[part 14 of 23: package /Cluster]
AUTOSAR XML (schema 4-3-0)
package /Cluster  (continued)
  7 x lin cluster, all with baudrate=19200, protocol-name=LIN, protocol-version=2.0:  (continued)
    Klima_LIN6
      lin physical channel CHNL: comm-connectors=CN_Klima_LIN6
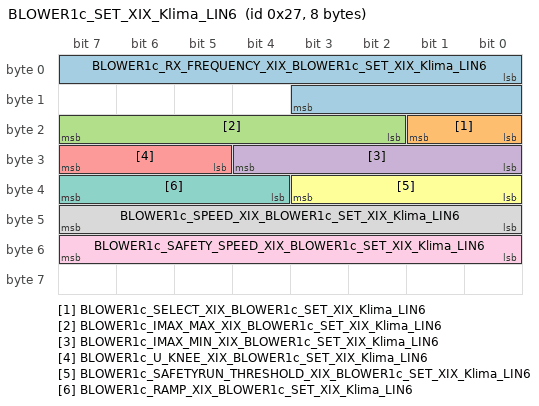
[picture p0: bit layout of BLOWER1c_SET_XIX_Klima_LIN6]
        frame BLOWER1c_SET_XIX_Klima_LIN6: id 0x27, from Klima, frame-length=8, lin-checksum=ENHANCED
          pdu BLOWER1c_SET_XIX_Klima_LIN6: length=8, unused-bit-pattern=0
            signal BLOWER1c_RX_FREQUENCY_XIX_BLOWER1c_SET_XIX_Klima_LIN6: start 0, 12 bit, little-endian, data-type-policy=OVERRIDE, i-signal-type=PRIMITIVE, base-type=BT_BLOWER1c_RX_FREQUENCY, compu {phys=raw+150 for raw 0..1896, 4095=Cxfff_ungueltig (CM_BLOWER1c_RX_FREQUENCY_Cxfff_ungueltig); unit Unit_KiloHertz}, range phys 150..2046 Unit_KiloHertz, raw 0..4095, unit=Unit_KiloHertz, transfer-property=PENDING  # Radio-Empfangsfrequenz bei AM-Empfang 0..1896: Radio RX-Frequenz in kHz 150 kHz.. 2046 kHz (Offset 150 kHz) diese Frequenz Störungsfrei halten. 1897 .. 4094 rerserviert, Ersatzwert: oberste einstellbare Frequenz 4095: ungueltig, Ersatzwert: oberste einstellbare Frequenz
            signal BLOWER1c_SELECT_XIX_BLOWER1c_SET_XIX_Klima_LIN6: start 16, 2 bit, little-endian, data-type-policy=OVERRIDE, i-signal-type=PRIMITIVE, init-value=0, base-type=BT_BLOWER1c_SELECT, compu {0=Cx0_BLOWER1 (CM_BLOWER1c_SELECT_Cx0_BLOWER1), 1=Cx1_BLOWER3 (CM_BLOWER1c_SELECT_Cx1_BLOWER3), 2=Cx2_reserviert (CM_BLOWER1c_SELECT_Cx2_reserviert), 3=Cx3_ungueltig (CM_BLOWER1c_SELECT_Cx3_ungueltig)}, range raw 0..3, transfer-property=PENDING  # 00 : Blower 1 wenn / when ID-field = 0x27 Blower 2 wenn / when ID-field = 0x3A 01 : Blower 3 wenn / when ID-field = 0x27 Blower 4 wenn/ when ID-field = 0x3A 10 : reserviert, Ersatzwert: Blower 2 11 : ungültig, Ersatzwert: Blower 2
            signal BLOWER1c_IMAX_MAX_XIX_BLOWER1c_SET_XIX_Klima_LIN6: start 18, 6 bit, little-endian, data-type-policy=OVERRIDE, i-signal-type=PRIMITIVE, init-value=0, base-type=BT_BLOWER1c_IMAX_MAX, compu {phys=raw*0.5+8 for raw 0..62, 63=Cx3f_ungueltig (CM_BLOWER1c_IMAX_MAX_Cx3f_ungueltig); unit Unit_Amper}, range phys 8..39 Unit_Amper, raw 0..63, unit=Unit_Amper, transfer-property=PENDING  # Vorgabe Maximalstrombegrenzung bei hoher Motorspannung 0.. 62 : Maximalstrom 8 A .. 39 A, Auflösung 0,5 A*inc + 8A. 63 : ungueltig Ersatzwert: niedrigster einstellbarer Wert Regler begrenzt auf Maximalwert
            signal BLOWER1c_IMAX_MIN_XIX_BLOWER1c_SET_XIX_Klima_LIN6: start 24, 5 bit, little-endian, data-type-policy=OVERRIDE, i-signal-type=PRIMITIVE, init-value=0, base-type=BT_BLOWER1c_IMAX_MIN, compu {phys=raw*0.5+2 for raw 0..30, 31=Cx1f_ungueltig (CM_BLOWER1c_IMAX_MIN_Cx1f_ungueltig); unit Unit_Amper}, range phys 2..17 Unit_Amper, raw 0..31, unit=Unit_Amper, transfer-property=PENDING  # Vorgabe Maximalstrombegrenzung bei kleiner Motorspannung (Umotor < 2 V) 0 .. 30 : Maximalstrom 2 A .. 17 A, Aufloesung 0,5 A*inc + 2 A. 31 : Ungueltig Ersatzwert: niedrigster einstellbarer Wert Der Geblaeseregler darf zu hohe oder zu kleine Vorgaben auf die applikationsspezifischen Werte begrenzen.
            signal BLOWER1c_U_KNEE_XIX_BLOWER1c_SET_XIX_Klima_LIN6: start 29, 3 bit, little-endian, data-type-policy=OVERRIDE, i-signal-type=PRIMITIVE, init-value=0, base-type=BT_BLOWER1c_U_KNEE, compu {phys=raw*0.5+8.5 for raw 0..6, 7=Cx7_ungueltig (CM_BLOWER1c_U_KNEE_Cx7_ungueltig); unit Unit_Volt}, range phys 8.5..11.5 Unit_Volt, raw 0..7, unit=Unit_Volt, transfer-property=PENDING  # Vorgabe Knickspannung Strombegrenzung 0 ¿ 6 : Knick bei Umot = 8,5 ¿ 11,5 V, Auflösung 0,5 V * inc + 8,5 V. 7 : Ungültig Ersatzwert 12.0 V Die Knickspannung wird entsprechend dem gesendeten Wert vom Regler eingestellt.
            signal BLOWER1c_SAFETYRUN_THRESHOLD_XIX_BLOWER1c_SET_XIX_Klima_LIN6: start 32, 4 bit, little-endian, data-type-policy=OVERRIDE, i-signal-type=PRIMITIVE, init-value=0, base-type=BT_BLOWER1c_SAFETYRUN_THRESHOLD, compu {phys=raw*0.1+11.5 for raw 0..14, 15=Cxf_ungueltig (CM_BLOWER1c_SAFETYRUN_THRESHOLD_Cxf_ungueltig); unit Unit_Volt}, range phys 11.5..12.9 Unit_Volt, raw 0..15, unit=Unit_Volt, transfer-property=PENDING  # Freigabe Notlauf und Schwellen 0 ... 14 : Schwelle Motor aus bei Ubatt < 11,5 V ¿ 12,9 V Auflösung 0,1 V * inc + 11,5 V 15 : Ungültig Schwelle Motor aus bei Ubatt < 13 V Entsprechend dem gesendeten Wert wird der Notlauf bei Unterschreiten der Batteriespannung abgeschaltet.
            signal BLOWER1c_RAMP_XIX_BLOWER1c_SET_XIX_Klima_LIN6: start 36, 4 bit, little-endian, data-type-policy=OVERRIDE, i-signal-type=PRIMITIVE, init-value=0, base-type=BT_BLOWER1c_RAMP, compu {0=Cx0_LessThan_0_12V_s_Testrampe (CM_BLOWER1c_RAMP_Cx0_LessThan_0_12V_s_Testrampe), phys=raw*0.5 for raw 1..14, 15=Cxf_ungueltig (CM_BLOWER1c_RAMP_Cxf_ungueltig); unit Unit_VoltPerSecon}, range phys 0.5..7 Unit_VoltPerSecon, raw 0..15, unit=Unit_VoltPerSecon, transfer-property=PENDING  # Vorgabe Rampenzeitkonstante DUmotor / s 0 : < 0,12 V / s (Testrampe) 1 .. 14: 0,5 V / sec. bis 7 V / s Auflösung: 0,5 V / s * inc 15 : Ungültig Ersatzwert 7.5 V / s
            signal BLOWER1c_SPEED_XIX_BLOWER1c_SET_XIX_Klima_LIN6: start 40, 8 bit, little-endian, data-type-policy=OVERRIDE, i-signal-type=PRIMITIVE, init-value=0, base-type=BT_BLOWER1c_SPEED, compu {0=Cx0_Motorspannung_0V (CM_BLOWER1c_SPEED_Cx0_Motorspannung_0V), phys=raw*0.05+1.45 for raw 1..251, 252=Cxfc_sofort_Abschalten_0V (CM_BLOWER1c_SPEED_Cxfc_sofort_Abschalten_0V), 253=Cxfd_senken_mit_Rampe_0V (CM_BLOWER1c_SPEED_Cxfd_senken_mit_Rampe_0V), 254=Cxfe_reserviert (CM_BLOWER1c_SPEED_Cxfe_reserviert), 255=Cxff_ungueltig (CM_BLOWER1c_SPEED_Cxff_ungueltig); unit Unit_Volt}, range phys 1.5..14 Unit_Volt, raw 0..255, unit=Unit_Volt, transfer-property=PENDING  # Vorgabe Sollwert Motorspannung 0 : 0 V 1 ... 251: 1,5 V bis 14,0 V Auflösung: 50 mV * inc + 1,45 V 1.5 V to 14.0 V 252 : 0 V sofort Abschalten 253 : 0 V Senken mit Rampe 254 : reserviert 255 : Ungültig Sofort Abschalten Der Gebläseregler darf zu hohe oder zu kleine Vorgaben auf die spezifizierten Werte begrenzen.
            signal BLOWER1c_SAFETY_SPEED_XIX_BLOWER1c_SET_XIX_Klima_LIN6: start 48, 8 bit, little-endian, data-type-policy=OVERRIDE, i-signal-type=PRIMITIVE, init-value=0, base-type=BT_BLOWER1c_SAFETY_SPEED, compu {phys=raw*0.05+1.5 for raw 0..250, 251=Cxfb_reserviert (CM_BLOWER1c_SAFETY_SPEED_Cxfb_reserviert), 252=Cxfc_reserviert (CM_BLOWER1c_SAFETY_SPEED_Cxfc_reserviert), 253=Cxfd_Notlauf_dis_sofort_Abschalten_0V (CM_BLOWER1c_SAFETY_SPEED_Cxfd_Notlauf_dis_sofort_Abschalten_0V), 254=Cxfe_Notlauf_disabled_0V (CM_BLOWER1c_SAFETY_SPEED_Cxfe_Notlauf_disabled_0V), 255=Cxff_ungueltig (CM_BLOWER1c_SAFETY_SPEED_Cxff_ungueltig); unit Unit_Volt}, range phys 1.5..14 Unit_Volt, raw 0..255, unit=Unit_Volt, transfer-property=PENDING  # Vorgabe Sollwert Notlaufmotorspannung 0 ... 252: 1,5 V bis 14,0 V Notlaufmotorspannung Auflösung: 50 mV * inc + 1,5 V 253 : 0 V, Notlauf disabled sofort Abschalten 254 : 0,0 V Notlauf disabled (senken mit Rampe) 255 : Ungültig Sofort Abschalten Der gesendete Wert wird eingestellt. Der Gebläseregler darf zu hohe oder zu kleine Vorgaben auf die spezifizierten Werte begrenzen.
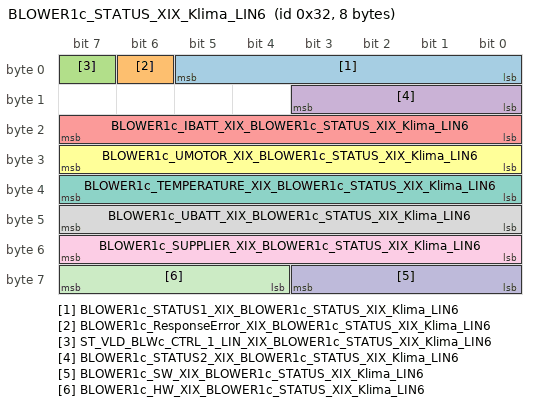
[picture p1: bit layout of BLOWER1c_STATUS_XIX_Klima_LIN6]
        frame BLOWER1c_STATUS_XIX_Klima_LIN6: id 0x32, to Klima, frame-length=8, lin-checksum=ENHANCED
          pdu BLOWER1c_STATUS_XIX_Klima_LIN6: length=8, unused-bit-pattern=0
            signal BLOWER1c_STATUS1_XIX_BLOWER1c_STATUS_XIX_Klima_LIN6: start 0, 6 bit, little-endian, data-type-policy=OVERRIDE, i-signal-type=PRIMITIVE, init-value=0, base-type=BT_BLOWER1c_STATUS1, compu {0=Cx0_Init (CM_BLOWER1c_STATUS1_Cx0_Init), 1=Cx1_int_Fehler_detektiert_Notabsch (CM_BLOWER1c_STATUS1_Cx1_int_Fehler_detektiert_Notabsch), 2=Cx2_Kurzschl_o_blockiert_Motor_aus (CM_BLOWER1c_STATUS1_Cx2_Kurzschl_o_blockiert_Motor_aus), 4=Cx4_Uebertemperaturbegrenzung_aktiv (CM_BLOWER1c_STATUS1_Cx4_Uebertemperaturbegrenzung_aktiv), 8=Cx8_Unterbrechung_zum_Motor_detekt (CM_BLOWER1c_STATUS1_Cx8_Unterbrechung_zum_Motor_detekt), 16=Cx10_Ueberspannung_Abschaltung (CM_BLOWER1c_STATUS1_Cx10_Ueberspannung_Abschaltung), 32=Cx20_Unterspannung_Abschaltung (CM_BLOWER1c_STATUS1_Cx20_Unterspannung_Abschaltung)}, range raw 0..32, transfer-property=PENDING, to Klima(timeout 3.5 s)  # Status Gebläseregler 2^0 : interner Fehler detektiert, Notabschaltung 2^1 : Kurzschluss oder blockiert, Motor aus 2^2 : Übertemperaturbegrenzung aktiv 2^3 : Unterbrechung zum Motor detektiert 2^4 : Überspannung Abschaltung 2^5 : Unterspannung Abschaltung
            signal BLOWER1c_ResponseError_XIX_BLOWER1c_STATUS_XIX_Klima_LIN6: start 6, 1 bit, little-endian, data-type-policy=OVERRIDE, i-signal-type=PRIMITIVE, init-value=0, base-type=BT_BLOWER1c_ResponseError, invalid-value=Invalid_BLOWER1c_ResponseError_XIX_BLOWER1c_STATUS_XIX_Klima_LIN6:1, compu {0=Cx0_normal (CM_BLOWER1c_ResponseError_Cx0_normal), 1=Cx1_Fehler (CM_BLOWER1c_ResponseError_Cx1_Fehler)}, range raw 0..1, transfer-property=PENDING, to Klima(timeout 3.5 s)  # siehe LIN2.0-Specification (Darf nicht über ein Fehlergueltigkeitsbit abgesichtert werden!)
            signal ST_VLD_BLWc_CTRL_1_LIN_XIX_BLOWER1c_STATUS_XIX_Klima_LIN6: start 7, 1 bit, little-endian, data-type-policy=OVERRIDE, i-signal-type=PRIMITIVE, init-value=0, base-type=BT_ST_VLD_BLWc_CTRL_1_LIN, compu {0=Cx0_normal (CM_ST_VLD_BLWc_CTRL_1_LIN_Cx0_normal), 1=Cx1_Blower_Status1_ungueltig_ignor (CM_ST_VLD_BLWc_CTRL_1_LIN_Cx1_Blower_Status1_ungueltig_ignor)}, range raw 0..1, transfer-property=PENDING, to Klima(timeout 3.5 s)  # Status Gebläseregler: 0: normal 1: Blower Status 1 ungültig, ignorieren
            signal BLOWER1c_STATUS2_XIX_BLOWER1c_STATUS_XIX_Klima_LIN6: start 8, 4 bit, little-endian, data-type-policy=OVERRIDE, i-signal-type=PRIMITIVE, init-value=0, base-type=BT_BLOWER1c_STATUS2, compu {0=Cx0_Init (CM_BLOWER1c_STATUS2_Cx0_Init), 1=Cx1_Strombegrenzung_aktiv (CM_BLOWER1c_STATUS2_Cx1_Strombegrenzung_aktiv), 2=Cx2_Sollwert_erreicht (CM_BLOWER1c_STATUS2_Cx2_Sollwert_erreicht), 4=Cx4_Notlauf_aktiviert (CM_BLOWER1c_STATUS2_Cx4_Notlauf_aktiviert), 8=Cx8_Blower_Status_2_ungultig_ignori (CM_BLOWER1c_STATUS2_Cx8_Blower_Status_2_ungultig_ignori)}, range raw 0..8, transfer-property=PENDING, to Klima(timeout 3.5 s)  # Status Gebläseregler 2^0 : Strombegrenzung aktiv 2^1 : Sollwert erreicht 2^2 : Notlauf aktiviert 2^3 : Blower Status 2 ungültig, ignorieren
            signal BLOWER1c_IBATT_XIX_BLOWER1c_STATUS_XIX_Klima_LIN6: start 16, 8 bit, little-endian, data-type-policy=OVERRIDE, i-signal-type=PRIMITIVE, init-value=0, base-type=BT_BLOWER1c_IBATT, compu {phys=raw*0.25 for raw 0..253, 254=Cxfe_kein_Messwert_verfuegbar (CM_BLOWER1c_IBATT_Cxfe_kein_Messwert_verfuegbar), 255=Cxff_Fehler_Strommesseinrichtung (CM_BLOWER1c_IBATT_Cxff_Fehler_Strommesseinrichtung); unit Unit_Amper}, range phys 0..63.25 Unit_Amper, raw 0..255, unit=Unit_Amper, transfer-property=PENDING, to Klima(timeout 3.5 s)  # Stromaufnahme Gebläseregler 0 ... 253: 0 A ... bis 63,25 A, Auflösung: 0,25 A / inc 254 : kein Messwert verfügbar 255 : Fehler Strommesseinrichtung
            signal BLOWER1c_UMOTOR_XIX_BLOWER1c_STATUS_XIX_Klima_LIN6: start 24, 8 bit, little-endian, data-type-policy=OVERRIDE, i-signal-type=PRIMITIVE, init-value=0, base-type=BT_BLOWER1c_UMOTOR, compu {phys=raw*0.1 for raw 0..253, 254=Cxfe_kein_Messwert_verfuegbar (CM_BLOWER1c_UMOTOR_Cxfe_kein_Messwert_verfuegbar), 255=Cxff_Fehler_Spannungsmesseinrichtung (CM_BLOWER1c_UMOTOR_Cxff_Fehler_Spannungsmesseinrichtung); unit Unit_Volt}, range phys 0..25.3 Unit_Volt, raw 0..255, unit=Unit_Volt, transfer-property=PENDING, to Klima(timeout 3.5 s)  # Spannung am Gebläsemotor Umot 0 ... 253 : 0 V ... 25,3 V, Auflösung/Resolution: 0,1 V / inc 254 : kein Messwert verfügbar 255 : Fehler Spannungsmesseinrichtung Der Messbereich des Gebläsereglers darf kleiner 25,3 V sein. Bei Bereichsüberschreitung ist 254 zurückzumelden.
            signal BLOWER1c_TEMPERATURE_XIX_BLOWER1c_STATUS_XIX_Klima_LIN6: start 32, 8 bit, little-endian, data-type-policy=OVERRIDE, i-signal-type=PRIMITIVE, init-value=0, base-type=BT_BLOWER1c_TEMPERATURE, compu {phys=raw-40 for raw 0..190, phys=150 for raw 191..253, 254=Cxfe_kein_Messwert_verfuegbar (CM_BLOWER1c_TEMPERATURE_Cxfe_kein_Messwert_verfuegbar) (kein Messwert verfügbar), 255=Cxff_Fehler_Temperaturmesseinrichtung (CM_BLOWER1c_TEMPERATURE_Cxff_Fehler_Temperaturmesseinrichtung) (Fehler Temperaturmesseinrichtung); unit Unit_DegreCelsi}, range phys 150 Unit_DegreCelsi, phys -40..150 Unit_DegreCelsi, raw 191..255, raw 0..255, unit=Unit_DegreCelsi, transfer-property=PENDING, to Klima(timeout 3.5 s)  # Temperatur Gebläseregler 0 ... 190 : -40 °C ... 150 °C, Auflösung / Resolution: 1 K / inc 191 ... 253 : 150 °C 254 : kein Messwert verfügbar 255 : Fehler Temperaturmesseinrichtung
            signal BLOWER1c_UBATT_XIX_BLOWER1c_STATUS_XIX_Klima_LIN6: start 40, 8 bit, little-endian, data-type-policy=OVERRIDE, i-signal-type=PRIMITIVE, init-value=0, base-type=BT_BLOWER1c_UBATT, compu {phys=raw*0.1 for raw 0..253, 254=Cxfe_kein_Messwert_verfuegbar (CM_BLOWER1c_UBATT_Cxfe_kein_Messwert_verfuegbar), 255=Cxff_Fehler_Spannungsmesseinrichtung (CM_BLOWER1c_UBATT_Cxff_Fehler_Spannungsmesseinrichtung); unit Unit_Volt}, range phys 0..25.3 Unit_Volt, raw 0..255, unit=Unit_Volt, transfer-property=PENDING, to Klima(timeout 3.5 s)  # Spannung am Gebläseregler UBatt 0 ... 253 : 0 V ... 25,3 V, Auflösung / Resolution: 0,1 V / inc 254 : kein Messwert verfügbar 255 : Fehler Spannungsmesseinrichtung
            signal BLOWER1c_SUPPLIER_XIX_BLOWER1c_STATUS_XIX_Klima_LIN6: start 48, 8 bit, little-endian, data-type-policy=OVERRIDE, i-signal-type=PRIMITIVE, init-value=0, base-type=BT_BLOWER1c_SUPPLIER, compu {phys=raw for raw 0..48, 64=Cx40_BOSCH (CM_BLOWER1c_SUPPLIER_Cx40_BOSCH), 102=Cx66_VALEO (CM_BLOWER1c_SUPPLIER_Cx66_VALEO); unit Unit_None}, range phys 0..48 Unit_None, raw 0..102, unit=Unit_None, transfer-property=PENDING, to Klima(timeout 3.5 s)  # Hersteller-Nummer 40h : BOSCH
            signal BLOWER1c_SW_XIX_BLOWER1c_STATUS_XIX_Klima_LIN6: start 56, 4 bit, little-endian, data-type-policy=OVERRIDE, i-signal-type=PRIMITIVE, init-value=0, base-type=BT_BLOWER1c_SW, compu {phys=raw for raw 0..15; unit Unit_None}, range phys 0..15 Unit_None, raw 0..15, unit=Unit_None, transfer-property=PENDING, to Klima(timeout 3.5 s)  # Software-Version 0..F: Version 1¿16
            signal BLOWER1c_HW_XIX_BLOWER1c_STATUS_XIX_Klima_LIN6: start 60, 4 bit, little-endian, data-type-policy=OVERRIDE, i-signal-type=PRIMITIVE, init-value=0, base-type=BT_BLOWER1c_HW, compu {phys=raw for raw 0..15; unit Unit_None}, range phys 0..15 Unit_None, raw 0..15, unit=Unit_None, transfer-property=PENDING, to Klima(timeout 3.5 s)  # Hardware-Version 0..F: Version 1¿16
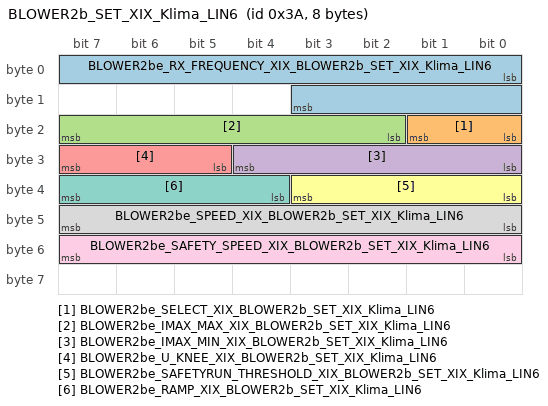
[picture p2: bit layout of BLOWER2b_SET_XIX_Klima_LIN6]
        frame BLOWER2b_SET_XIX_Klima_LIN6: id 0x3A, from Klima, frame-length=8, lin-checksum=ENHANCED
          pdu BLOWER2b_SET_XIX_Klima_LIN6: length=8, unused-bit-pattern=0
            signal BLOWER2be_RX_FREQUENCY_XIX_BLOWER2b_SET_XIX_Klima_LIN6: start 0, 12 bit, little-endian, data-type-policy=OVERRIDE, i-signal-type=PRIMITIVE, init-value=0, base-type=BT_BLOWER2be_RX_FREQUENCY, compu {phys=raw+150 for raw 0..1896, 4095=Cxfff_ungueltig (CM_BLOWER2be_RX_FREQUENCY_Cxfff_ungueltig); unit Unit_KiloHertz}, range phys 150..2046 Unit_KiloHertz, raw 0..4095, unit=Unit_KiloHertz, transfer-property=PENDING  # Radio-Empfangsfrequenz bei AM-Empfang 0..1896: Radio RX-Frequenz in kHz 150 kHz.. 2046 kHz (Offset 150 kHz) diese Frequenz Störungsfrei halten. 1897 .. 4094 rerserviert, Ersatzwert: oberste einstellbare Frequenz 4095: ungueltig, Ersatzwert: oberste einstellbare Frequenz
            signal BLOWER2be_SELECT_XIX_BLOWER2b_SET_XIX_Klima_LIN6: start 16, 2 bit, little-endian, data-type-policy=OVERRIDE, i-signal-type=PRIMITIVE, init-value=0, base-type=BT_BLOWER2be_SELECT, compu {0=Cx0_BLOWER2 (CM_BLOWER2be_SELECT_Cx0_BLOWER2), 1=Cx1_BLOWER4 (CM_BLOWER2be_SELECT_Cx1_BLOWER4), 2=Cx2_reserviert (CM_BLOWER2be_SELECT_Cx2_reserviert), 3=Cx3_ungueltig (CM_BLOWER2be_SELECT_Cx3_ungueltig)}, range raw 0..3, transfer-property=PENDING  # 00 : Blower 1 wenn / when ID-field = 0x27 Blower 2 wenn / when ID-field = 0x3A 01 : Blower 3 wenn / when ID-field = 0x27 Blower 4 wenn/ when ID-field = 0x3A 10 : reserviert, Ersatzwert: Blower 2 11 : ungültig, Ersatzwert: Blower 2
            signal BLOWER2be_IMAX_MAX_XIX_BLOWER2b_SET_XIX_Klima_LIN6: start 18, 6 bit, little-endian, data-type-policy=OVERRIDE, i-signal-type=PRIMITIVE, init-value=0, base-type=BT_BLOWER2be_IMAX_MAX, compu {phys=raw*0.5+8 for raw 0..62, 63=Cx3f_ungueltig (CM_BLOWER2be_IMAX_MAX_Cx3f_ungueltig); unit Unit_Amper}, range phys 8..39 Unit_Amper, raw 0..63, unit=Unit_Amper, transfer-property=PENDING  # Vorgabe Maximalstrombegrenzung bei hoher Motorspannung 0.. 62 : Maximalstrom 8 A .. 39 A, Auflösung 0,5 A*inc + 8A. 63 : ungueltig Ersatzwert: niedrigster einstellbarer Wert Regler begrenzt auf Maximalwert
            signal BLOWER2be_IMAX_MIN_XIX_BLOWER2b_SET_XIX_Klima_LIN6: start 24, 5 bit, little-endian, data-type-policy=OVERRIDE, i-signal-type=PRIMITIVE, init-value=0, base-type=BT_BLOWER2be_IMAX_MIN, compu {phys=raw*0.5+2 for raw 0..30, 31=Cx1f_ungueltig (CM_BLOWER2be_IMAX_MIN_Cx1f_ungueltig); unit Unit_Amper}, range phys 2..17 Unit_Amper, raw 0..31, unit=Unit_Amper, transfer-property=PENDING  # Vorgabe Maximalstrombegrenzung bei kleiner Motorspannung (Umotor < 2 V) 0 .. 30 : Maximalstrom 2 A .. 17 A, Aufloesung 0,5 A*inc + 2 A. 31 : Ungueltig Ersatzwert: niedrigster einstellbarer Wert Der Geblaeseregler darf zu hohe oder zu kleine Vorgaben auf die applikationsspezifischen Werte begrenzen.
            signal BLOWER2be_U_KNEE_XIX_BLOWER2b_SET_XIX_Klima_LIN6: start 29, 3 bit, little-endian, data-type-policy=OVERRIDE, i-signal-type=PRIMITIVE, init-value=0, base-type=BT_BLOWER2be_U_KNEE, compu {phys=raw*0.5+8.5 for raw 0..6, 7=Cx7_ungueltig (CM_BLOWER2be_U_KNEE_Cx7_ungueltig); unit Unit_Volt}, range phys 8.5..11.5 Unit_Volt, raw 0..7, unit=Unit_Volt, transfer-property=PENDING  # Vorgabe Knickspannung Strombegrenzung 0.. 6 : Knick bei Umot = 8,5.. 11,5 V, Auflösung 0,5 V * inc + 8,5 V. 7 : Ungültig Ersatzwert 12.0 V Die Knickspannung wird entsprechend dem gesendeten Wert vom Regler eingestellt.
            signal BLOWER2be_SAFETYRUN_THRESHOLD_XIX_BLOWER2b_SET_XIX_Klima_LIN6: start 32, 4 bit, little-endian, data-type-policy=OVERRIDE, i-signal-type=PRIMITIVE, init-value=0, base-type=BT_BLOWER2be_SAFETYRUN_THRESHOLD, compu {phys=raw*0.1+11.5 for raw 0..14, 15=Cxf_ungueltig (CM_BLOWER2be_SAFETYRUN_THRESHOLD_Cxf_ungueltig); unit Unit_Volt}, range phys 11.5..12.9 Unit_Volt, raw 0..15, unit=Unit_Volt, transfer-property=PENDING  # Freigabe Notlauf und Schwellen 0 ... 14 : Schwelle Motor aus bei Ubatt < 11,5 V .. 12,9 V Auflösung 0,1 V * inc + 11,5 V 15 : Ungültig Schwelle Motor aus bei Ubatt < 13 V Entsprechend dem gesendeten Wert wird der Notlauf bei Unterschreiten der Batteriespannung abgeschaltet.
            signal BLOWER2be_RAMP_XIX_BLOWER2b_SET_XIX_Klima_LIN6: start 36, 4 bit, little-endian, data-type-policy=OVERRIDE, i-signal-type=PRIMITIVE, init-value=0, base-type=BT_BLOWER2be_RAMP, compu {0=Cx0_kleiner_120_mV_pro_s_Testrampe (CM_BLOWER2be_RAMP_Cx0_kleiner_120_mV_pro_s_Testrampe) (kleiner_120_mV_pro_s__Testrampe), phys=raw*0.5 for raw 1..14, 15=Cxf_ungueltig (CM_BLOWER2be_RAMP_Cxf_ungueltig); unit Unit_VoltPerSecon}, range phys 0.5..7 Unit_VoltPerSecon, raw 0..15, unit=Unit_VoltPerSecon, transfer-property=PENDING  # Vorgabe Rampenzeitkonstante DUmotor / s 0 : < 0,12 V / s (Testrampe) 1 .. 14: 0,5 V / sec. bis 7 V / s Auflösung: 0,5 V / s * inc 15 : Ungültig Ersatzwert 7.5 V / s
            signal BLOWER2be_SPEED_XIX_BLOWER2b_SET_XIX_Klima_LIN6: start 40, 8 bit, little-endian, data-type-policy=OVERRIDE, i-signal-type=PRIMITIVE, init-value=0, base-type=BT_BLOWER2be_SPEED, compu {0=Cx0_0V_Motorspannung (CM_BLOWER2be_SPEED_Cx0_0V_Motorspannung), phys=raw*0.05+1.45 for raw 1..251, 252=Cxfc_0V_sofort_Abschalten (CM_BLOWER2be_SPEED_Cxfc_0V_sofort_Abschalten), 253=Cxfd_0V_senken_mit_Rampe (CM_BLOWER2be_SPEED_Cxfd_0V_senken_mit_Rampe), 254=Cxfe_reserviert (CM_BLOWER2be_SPEED_Cxfe_reserviert), 255=Cxff_ungueltig (CM_BLOWER2be_SPEED_Cxff_ungueltig); unit Unit_Volt}, range phys 1.5..14 Unit_Volt, raw 0..255, unit=Unit_Volt, transfer-property=PENDING  # Vorgabe Sollwert Motorspannung 0 : 0 V 1 ... 251: 1,5 V bis 14,0 V Auflösung: 50 mV * inc + 1,45 V 1.5 V to 14.0 V 252 : 0 V sofort Abschalten 253 : 0 V Senken mit Rampe 254 : reserviert 255 : Ungültig Sofort Abschalten Der Gebläseregler darf zu hohe oder zu kleine Vorgaben auf die spezifizierten Werte begrenzen.
            signal BLOWER2be_SAFETY_SPEED_XIX_BLOWER2b_SET_XIX_Klima_LIN6: start 48, 8 bit, little-endian, data-type-policy=OVERRIDE, i-signal-type=PRIMITIVE, init-value=0, base-type=BT_BLOWER2be_SAFETY_SPEED, compu {phys=raw*0.05+1.5 for raw 0..250, 251=Cxfb_reserviert (CM_BLOWER2be_SAFETY_SPEED_Cxfb_reserviert), 252=Cxfc_reserviert (CM_BLOWER2be_SAFETY_SPEED_Cxfc_reserviert), 253=Cxfd_0V_Notlauf_disabled_sofort_absch (CM_BLOWER2be_SAFETY_SPEED_Cxfd_0V_Notlauf_disabled_sofort_absch), 254=Cxfe_0V_Notlauf_disabled (CM_BLOWER2be_SAFETY_SPEED_Cxfe_0V_Notlauf_disabled), 255=Cxff_ungueltig (CM_BLOWER2be_SAFETY_SPEED_Cxff_ungueltig); unit Unit_Volt}, range phys 1.5..14 Unit_Volt, raw 0..255, unit=Unit_Volt, transfer-property=PENDING  # Vorgabe Sollwert Notlaufmotorspannung 0 ... 252: 1,5 V bis 14,0 V Notlaufmotorspannung Auflösung: 50 mV * inc + 1,5 V 253 : 0 V, Notlauf disabled sofort Abschalten 254 : 0,0 V Notlauf disabled (senken mit Rampe) 255 : Ungültig Sofort Abschalten Der gesendete Wert wird eingestellt. Der Gebläseregler darf zu hohe oder zu kleine Vorgaben auf die spezifizierten Werte begrenzen.
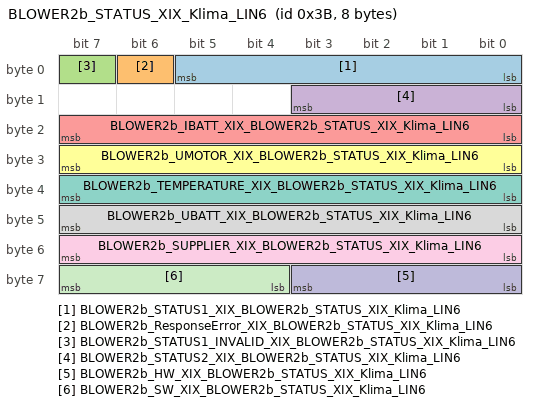
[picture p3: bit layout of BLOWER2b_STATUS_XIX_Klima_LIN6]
        frame BLOWER2b_STATUS_XIX_Klima_LIN6: id 0x3B, to Klima, frame-length=8, lin-checksum=ENHANCED
          pdu BLOWER2b_STATUS_XIX_Klima_LIN6: length=8, unused-bit-pattern=0
            signal BLOWER2b_STATUS1_XIX_BLOWER2b_STATUS_XIX_Klima_LIN6: start 0, 6 bit, little-endian, data-type-policy=OVERRIDE, i-signal-type=PRIMITIVE, init-value=0, base-type=BT_BLOWER2b_STATUS1, compu {0=Cx0_Init (CM_BLOWER2b_STATUS1_Cx0_Init), 1=Cx1_interner_Fehler_Notabschaltung (CM_BLOWER2b_STATUS1_Cx1_interner_Fehler_Notabschaltung) (interner_Fehler__Notabschaltung), 2=Cx2_Kurzschluss_blockiert_Motor_aus (CM_BLOWER2b_STATUS1_Cx2_Kurzschluss_blockiert_Motor_aus) (Kurzschluss_blockiert__Motor_aus), 4=Cx4_Uebertemperaturbegrenzung_aktiv (CM_BLOWER2b_STATUS1_Cx4_Uebertemperaturbegrenzung_aktiv), 8=Cx8_Unterbrechung_zum_Motor (CM_BLOWER2b_STATUS1_Cx8_Unterbrechung_zum_Motor), 16=Cx10_Ueberspannung_Abschaltung (CM_BLOWER2b_STATUS1_Cx10_Ueberspannung_Abschaltung), 32=Cx20_Unterspannung_Abschaltung (CM_BLOWER2b_STATUS1_Cx20_Unterspannung_Abschaltung)}, range raw 0..32, transfer-property=PENDING, to Klima(timeout 3.5 s)  # Status Gebläseregler 2^0 : interner Fehler detektiert, Notabschaltung 2^1 : Kurzschluss oder blockiert, Motor aus 2^2 : Übertemperaturbegrenzung aktiv 2^3 : Unterbrechung zum Motor detektiert 2^4 : Überspannung Abschaltung 2^5 : Unterspannung Abschaltung
            signal BLOWER2b_ResponseError_XIX_BLOWER2b_STATUS_XIX_Klima_LIN6: start 6, 1 bit, little-endian, data-type-policy=OVERRIDE, i-signal-type=PRIMITIVE, init-value=0, base-type=BT_BLOWER2b_ResponseError, invalid-value=Invalid_BLOWER2b_ResponseError_XIX_BLOWER2b_STATUS_XIX_Klima_LIN6:1, compu {0=Cx0_normal (CM_BLOWER2b_ResponseError_Cx0_normal), 1=Cx1_Fehler (CM_BLOWER2b_ResponseError_Cx1_Fehler)}, range raw 0..1, transfer-property=PENDING, to Klima(timeout 3.5 s)  # siehe LIN2.0-Specification (Darf nicht über ein Fehlergueltigkeitsbit abgesichtert werden!)
            signal BLOWER2b_STATUS1_INVALID_XIX_BLOWER2b_STATUS_XIX_Klima_LIN6: start 7, 1 bit, little-endian, data-type-policy=OVERRIDE, i-signal-type=PRIMITIVE, init-value=0, base-type=BT_BLOWER2b_STATUS1_INVALID, compu {0=Cx0_normal (CM_BLOWER2b_STATUS1_INVALID_Cx0_normal), 1=Cx1_Status1_ungueltig_ignorieren (CM_BLOWER2b_STATUS1_INVALID_Cx1_Status1_ungueltig_ignorieren) (Status1_ungueltig__ignorieren)}, range raw 0..1, transfer-property=PENDING, to Klima(timeout 3.5 s)  # Status Gebläseregler: 0: normal 1: Blower Status 1 ungültig, ignorieren
            signal BLOWER2b_STATUS2_XIX_BLOWER2b_STATUS_XIX_Klima_LIN6: start 8, 4 bit, little-endian, data-type-policy=OVERRIDE, i-signal-type=PRIMITIVE, init-value=0, base-type=BT_BLOWER2b_STATUS2, compu {0=Cx0_Init (CM_BLOWER2b_STATUS2_Cx0_Init), 1=Cx1_Strombegrenzung_aktiv (CM_BLOWER2b_STATUS2_Cx1_Strombegrenzung_aktiv), 2=Cx2_Sollwert_erreicht (CM_BLOWER2b_STATUS2_Cx2_Sollwert_erreicht), 4=Cx4_Notlauf_aktiviert (CM_BLOWER2b_STATUS2_Cx4_Notlauf_aktiviert), 8=Cx8_ungueltig_ignorieren (CM_BLOWER2b_STATUS2_Cx8_ungueltig_ignorieren) (ungueltig__ignorieren)}, range raw 0..8, transfer-property=PENDING, to Klima(timeout 3.5 s)  # Status Gebläseregler 2^0 : Strombegrenzung aktiv 2^1 : Sollwert erreicht 2^2 : Notlauf aktiviert 2^3 : Blower Status 2 ungültig, ignorieren
            signal BLOWER2b_IBATT_XIX_BLOWER2b_STATUS_XIX_Klima_LIN6: start 16, 8 bit, little-endian, data-type-policy=OVERRIDE, i-signal-type=PRIMITIVE, init-value=0, base-type=BT_BLOWER2b_IBATT, compu {phys=raw*0.25 for raw 0..253, 254=Cxfe_kein_Messwert_verfuegbar (CM_BLOWER2b_IBATT_Cxfe_kein_Messwert_verfuegbar), 255=Cxff_Fehler_Strommesseinrichtung (CM_BLOWER2b_IBATT_Cxff_Fehler_Strommesseinrichtung); unit Unit_Amper}, range phys 0..63.25 Unit_Amper, raw 0..255, unit=Unit_Amper, transfer-property=PENDING, to Klima(timeout 3.5 s)  # Stromaufnahme Gebläseregler 0 ... 253: 0 A ... bis 63,25 A, Auflösung: 0,25 A / inc 254 : kein Messwert verfügbar 255 : Fehler Strommesseinrichtung
            signal BLOWER2b_UMOTOR_XIX_BLOWER2b_STATUS_XIX_Klima_LIN6: start 24, 8 bit, little-endian, data-type-policy=OVERRIDE, i-signal-type=PRIMITIVE, init-value=0, base-type=BT_BLOWER2b_UMOTOR, compu {phys=raw*0.1 for raw 0..253, 254=Cxfe_kein_Messwert_verfuegbar (CM_BLOWER2b_UMOTOR_Cxfe_kein_Messwert_verfuegbar), 255=Cxff_Fehler_Spannungsmesseinrichtung (CM_BLOWER2b_UMOTOR_Cxff_Fehler_Spannungsmesseinrichtung); unit Unit_Volt}, range phys 0..25.3 Unit_Volt, raw 0..255, unit=Unit_Volt, transfer-property=PENDING, to Klima(timeout 3.5 s)  # Spannung am Gebläsemotor Umot 0 ... 253 : 0 V ... 25,3 V, Auflösung/Resolution: 0,1 V / inc 254 : kein Messwert verfügbar 255 : Fehler Spannungsmesseinrichtung Der Messbereich des Gebläsereglers darf kleiner 25,3 V sein. Bei Bereichsüberschreitung ist 254 zurückzumelden.
            signal BLOWER2b_TEMPERATURE_XIX_BLOWER2b_STATUS_XIX_Klima_LIN6: start 32, 8 bit, little-endian, data-type-policy=OVERRIDE, i-signal-type=PRIMITIVE, init-value=0, base-type=BT_BLOWER2b_TEMPERATURE, compu {phys=raw-40 for raw 0..190, 254=Cxfe_kein_Messwert_verfuegbar (CM_BLOWER2b_TEMPERATURE_Cxfe_kein_Messwert_verfuegbar), 255=Cxff_Fehler_Temperaturmesseinrichtung (CM_BLOWER2b_TEMPERATURE_Cxff_Fehler_Temperaturmesseinrichtung); unit Unit_DegreCelsi}, range phys -40..150 Unit_DegreCelsi, raw 0..255, unit=Unit_DegreCelsi, transfer-property=PENDING, to Klima(timeout 3.5 s)  # Temperatur Gebläseregler 0 ... 190 : -40 °C ... 150 °C, Auflösung / Resolution: 1 K / inc 191 ... 253 : 150 °C 254 : kein Messwert verfügbar 255 : Fehler Temperaturmesseinrichtung
            signal BLOWER2b_UBATT_XIX_BLOWER2b_STATUS_XIX_Klima_LIN6: start 40, 8 bit, little-endian, data-type-policy=OVERRIDE, i-signal-type=PRIMITIVE, init-value=254, base-type=BT_BLOWER2b_UBATT, compu {phys=raw*0.1 for raw 0..253, 254=Cxfe_kein_Messwert_verfuegbar (CM_BLOWER2b_UBATT_Cxfe_kein_Messwert_verfuegbar), 255=Cxff_Fehler_Spannungsmesseinrichtung (CM_BLOWER2b_UBATT_Cxff_Fehler_Spannungsmesseinrichtung); unit Unit_Volt}, range phys 0..25.3 Unit_Volt, raw 0..255, unit=Unit_Volt, transfer-property=PENDING, to Klima(timeout 3.5 s)  # Spannung am Gebläseregler UBatt 0 ... 253 : 0 V ... 25,3 V, Auflösung / Resolution: 0,1 V / inc 254 : kein Messwert verfügbar 255 : Fehler Spannungsmesseinrichtung
            signal BLOWER2b_SUPPLIER_XIX_BLOWER2b_STATUS_XIX_Klima_LIN6: start 48, 8 bit, little-endian, data-type-policy=OVERRIDE, i-signal-type=PRIMITIVE, init-value=0, base-type=BT_BLOWER2b_SUPPLIER, compu {phys=raw for raw 0..48, 64=Cx40_BOSCH (CM_BLOWER2b_SUPPLIER_Cx40_BOSCH), 102=Cx66_VALEO (CM_BLOWER2b_SUPPLIER_Cx66_VALEO); unit Unit_None}, range phys 0..48 Unit_None, raw 0..102, unit=Unit_None, transfer-property=PENDING, to Klima(timeout 3.5 s)  # Hersteller-Nummer 40h : BOSCH 66h : VALEO
            signal BLOWER2b_HW_XIX_BLOWER2b_STATUS_XIX_Klima_LIN6: start 56, 4 bit, little-endian, data-type-policy=OVERRIDE, i-signal-type=PRIMITIVE, base-type=BT_BLOWER2b_HW, compu {phys=raw for raw 0..15; unit Unit_None}, range phys 0..15 Unit_None, raw 0..15, unit=Unit_None, transfer-property=PENDING, to Klima(timeout 3.5 s)  # Hardware-Version 0..F: Version 1 ...16
            signal BLOWER2b_SW_XIX_BLOWER2b_STATUS_XIX_Klima_LIN6: start 60, 4 bit, little-endian, data-type-policy=OVERRIDE, i-signal-type=PRIMITIVE, base-type=BT_BLOWER2b_SW, compu {phys=raw for raw 0..15; unit Unit_None}, range phys 0..15 Unit_None, raw 0..15, unit=Unit_None, transfer-property=PENDING, to Klima(timeout 3.5 s)  # Software-Version 0..F: Version 1 ...16
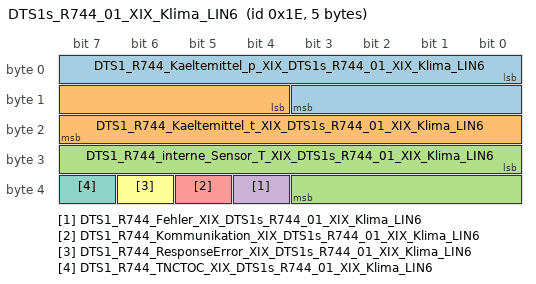
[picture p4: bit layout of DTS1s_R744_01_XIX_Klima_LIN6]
        frame DTS1s_R744_01_XIX_Klima_LIN6: id 0x1E, to Klima, frame-length=5, lin-checksum=ENHANCED
          pdu DTS1s_R744_01_XIX_Klima_LIN6: length=5, unused-bit-pattern=0
            signal DTS1_R744_Kaeltemittel_p_XIX_DTS1s_R744_01_XIX_Klima_LIN6: start 0, 12 bit, little-endian, data-type-policy=OVERRIDE, i-signal-type=PRIMITIVE, init-value=4094, base-type=BT_DTS1_R744_Kaeltemittel_p, invalid-value=Invalid_DTS1_R744_Kaeltemittel_p_XIX_DTS1s_R744_01_XIX_Klima_LIN6:4095, compu {phys=raw*0.05 for raw 0..3400, 4094=Cxffe_Init (CM_DTS1_R744_Kaeltemittel_p_Cxffe_Init), 4095=Cxfff_Fehler (CM_DTS1_R744_Kaeltemittel_p_Cxfff_Fehler); unit Unit_Bar}, range phys 0..170 Unit_Bar, raw 0..4095, unit=Unit_Bar, transfer-property=PENDING, to Klima(timeout 3.5 s)  # Kaeltemitteldruck absolut
            signal DTS1_R744_Kaeltemittel_t_XIX_DTS1s_R744_01_XIX_Klima_LIN6: start 12, 12 bit, little-endian, data-type-policy=OVERRIDE, i-signal-type=PRIMITIVE, init-value=4094, base-type=BT_DTS1_R744_Kaeltemittel_t, invalid-value=Invalid_DTS1_R744_Kaeltemittel_t_XIX_DTS1s_R744_01_XIX_Klima_LIN6:4095, compu {phys=raw*0.1-40 for raw 0..2200, 4094=Cxffe_Init (CM_DTS1_R744_Kaeltemittel_t_Cxffe_Init), 4095=Cxfff_Fehler (CM_DTS1_R744_Kaeltemittel_t_Cxfff_Fehler); unit Unit_DegreCelsi}, range phys -40..180 Unit_DegreCelsi, raw 0..4095, unit=Unit_DegreCelsi, transfer-property=PENDING, to Klima(timeout 3.5 s)  # Kältemitteltemperatur
            signal DTS1_R744_interne_Sensor_T_XIX_DTS1s_R744_01_XIX_Klima_LIN6: start 24, 12 bit, little-endian, data-type-policy=OVERRIDE, i-signal-type=PRIMITIVE, init-value=4094, base-type=BT_DTS1_R744_interne_Sensor_T, invalid-value=Invalid_DTS1_R744_interne_Sensor_T_XIX_DTS1s_R744_01_XIX_Klima_LIN6:4095, compu {phys=raw*0.1-40 for raw 0..1800, 4094=Cxffe_Init (CM_DTS1_R744_interne_Sensor_T_Cxffe_Init), 4095=Cxfff_Fehler (CM_DTS1_R744_interne_Sensor_T_Cxfff_Fehler); unit Unit_DegreCelsi}, range phys -40..140 Unit_DegreCelsi, raw 0..4095, unit=Unit_DegreCelsi, transfer-property=PENDING, to Klima(timeout 3.5 s)  # interne Sensor-Temperatur
            signal DTS1_R744_Fehler_XIX_DTS1s_R744_01_XIX_Klima_LIN6: start 36, 1 bit, little-endian, data-type-policy=OVERRIDE, i-signal-type=PRIMITIVE, init-value=0, base-type=BT_DTS1_R744_Fehler, invalid-value=Invalid_DTS1_R744_Fehler_XIX_DTS1s_R744_01_XIX_Klima_LIN6:1, compu {0=Cx0_kein_Fehler (CM_DTS1_R744_Fehler_Cx0_kein_Fehler), 1=Cx1_Fehler (CM_DTS1_R744_Fehler_Cx1_Fehler)}, range raw 0..1, transfer-property=PENDING, to Klima(timeout 3.5 s)  # Interner Sensorfehler
            signal DTS1_R744_Kommunikation_XIX_DTS1s_R744_01_XIX_Klima_LIN6: start 37, 1 bit, little-endian, data-type-policy=OVERRIDE, i-signal-type=PRIMITIVE, init-value=0, base-type=BT_DTS1_R744_Kommunikation, invalid-value=Invalid_DTS1_R744_Kommunikation_XIX_DTS1s_R744_01_XIX_Klima_LIN6:1, compu {0=Cx0_kein_Fehler (CM_DTS1_R744_Kommunikation_Cx0_kein_Fehler), 1=Cx1_Fehler (CM_DTS1_R744_Kommunikation_Cx1_Fehler)}, range raw 0..1, transfer-property=PENDING, to Klima(timeout 3.5 s)  # Checksummenfehler
            signal DTS1_R744_ResponseError_XIX_DTS1s_R744_01_XIX_Klima_LIN6: start 38, 1 bit, little-endian, data-type-policy=OVERRIDE, i-signal-type=PRIMITIVE, init-value=0, base-type=BT_DTS1_R744_ResponseError, invalid-value=Invalid_DTS1_R744_ResponseError_XIX_DTS1s_R744_01_XIX_Klima_LIN6:1, compu {0=Cx0_kein_Fehler (CM_DTS1_R744_ResponseError_Cx0_kein_Fehler), 1=Cx1_Fehler (CM_DTS1_R744_ResponseError_Cx1_Fehler)}, range raw 0..1, transfer-property=PENDING, to Klima(timeout 3.5 s)  # siehe LIN2.0-Specification (Darf nicht über ein Fehlergueltigkeitsbit abgesichtert werden!)
            signal DTS1_R744_TNCTOC_XIX_DTS1s_R744_01_XIX_Klima_LIN6: start 39, 1 bit, little-endian, data-type-policy=OVERRIDE, i-signal-type=PRIMITIVE, init-value=1, base-type=BT_DTS1_R744_TNCTOC, compu {0=Cx0_DTC_test_completed_this_operation_cylce (CM_DTS1_R744_TNCTOC_Cx0_DTC_test_completed_this_operation_cylce), 1=Cx1_DTC_test_not_completed_this_operation_cylce (CM_DTS1_R744_TNCTOC_Cx1_DTC_test_not_completed_this_operation_cylce)}, range raw 0..1, transfer-property=PENDING, to Klima(timeout 3.5 s)  # testNotCompletedThisOperationCycle (TNCTOC)
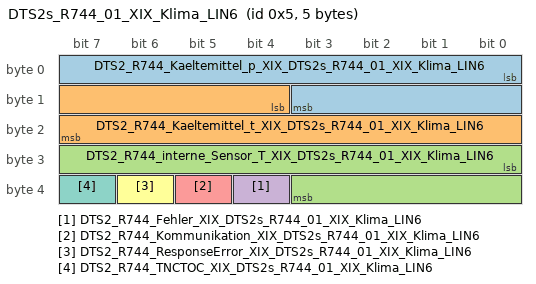
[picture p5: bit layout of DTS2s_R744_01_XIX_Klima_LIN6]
        frame DTS2s_R744_01_XIX_Klima_LIN6: id 0x5, to Klima, frame-length=5, lin-checksum=ENHANCED
          pdu DTS2s_R744_01_XIX_Klima_LIN6: length=5, unused-bit-pattern=0
            signal DTS2_R744_Kaeltemittel_p_XIX_DTS2s_R744_01_XIX_Klima_LIN6: start 0, 12 bit, little-endian, data-type-policy=OVERRIDE, i-signal-type=PRIMITIVE, init-value=4094, base-type=BT_DTS2_R744_Kaeltemittel_p, invalid-value=Invalid_DTS2_R744_Kaeltemittel_p_XIX_DTS2s_R744_01_XIX_Klima_LIN6:4095, compu {phys=raw*0.05 for raw 0..3400, 4094=Cxffe_Init (CM_DTS2_R744_Kaeltemittel_p_Cxffe_Init), 4095=Cxfff_Fehler (CM_DTS2_R744_Kaeltemittel_p_Cxfff_Fehler); unit Unit_Bar}, range phys 0..170 Unit_Bar, raw 0..4095, unit=Unit_Bar, transfer-property=PENDING, to Klima(timeout 3.5 s)  # Kaeltemitteldruck absolut
            signal DTS2_R744_Kaeltemittel_t_XIX_DTS2s_R744_01_XIX_Klima_LIN6: start 12, 12 bit, little-endian, data-type-policy=OVERRIDE, i-signal-type=PRIMITIVE, init-value=4094, base-type=BT_DTS2_R744_Kaeltemittel_t, invalid-value=Invalid_DTS2_R744_Kaeltemittel_t_XIX_DTS2s_R744_01_XIX_Klima_LIN6:4095, compu {phys=raw*0.1-40 for raw 0..2200, 4094=Cxffe_Init (CM_DTS2_R744_Kaeltemittel_t_Cxffe_Init), 4095=Cxfff_Fehler (CM_DTS2_R744_Kaeltemittel_t_Cxfff_Fehler); unit Unit_DegreCelsi}, range phys -40..180 Unit_DegreCelsi, raw 0..4095, unit=Unit_DegreCelsi, transfer-property=PENDING, to Klima(timeout 3.5 s)  # Kältemitteltemperatur
            signal DTS2_R744_interne_Sensor_T_XIX_DTS2s_R744_01_XIX_Klima_LIN6: start 24, 12 bit, little-endian, data-type-policy=OVERRIDE, i-signal-type=PRIMITIVE, init-value=4094, base-type=BT_DTS2_R744_interne_Sensor_T, invalid-value=Invalid_DTS2_R744_interne_Sensor_T_XIX_DTS2s_R744_01_XIX_Klima_LIN6:4095, compu {phys=raw*0.1-40 for raw 0..1800, 4094=Cxffe_Init (CM_DTS2_R744_interne_Sensor_T_Cxffe_Init), 4095=Cxfff_Fehler (CM_DTS2_R744_interne_Sensor_T_Cxfff_Fehler); unit Unit_DegreCelsi}, range phys -40..140 Unit_DegreCelsi, raw 0..4095, unit=Unit_DegreCelsi, transfer-property=PENDING, to Klima(timeout 3.5 s)  # interne Sensor-Temperatur
            signal DTS2_R744_Fehler_XIX_DTS2s_R744_01_XIX_Klima_LIN6: start 36, 1 bit, little-endian, data-type-policy=OVERRIDE, i-signal-type=PRIMITIVE, init-value=0, base-type=BT_DTS2_R744_Fehler, invalid-value=Invalid_DTS2_R744_Fehler_XIX_DTS2s_R744_01_XIX_Klima_LIN6:1, compu {0=Cx0_kein_Fehler (CM_DTS2_R744_Fehler_Cx0_kein_Fehler), 1=Cx1_Fehler (CM_DTS2_R744_Fehler_Cx1_Fehler)}, range raw 0..1, transfer-property=PENDING, to Klima(timeout 3.5 s)  # Interner Sensorfehler
            signal DTS2_R744_Kommunikation_XIX_DTS2s_R744_01_XIX_Klima_LIN6: start 37, 1 bit, little-endian, data-type-policy=OVERRIDE, i-signal-type=PRIMITIVE, init-value=0, base-type=BT_DTS2_R744_Kommunikation, invalid-value=Invalid_DTS2_R744_Kommunikation_XIX_DTS2s_R744_01_XIX_Klima_LIN6:1, compu {0=Cx0_kein_Fehler (CM_DTS2_R744_Kommunikation_Cx0_kein_Fehler), 1=Cx1_Fehler (CM_DTS2_R744_Kommunikation_Cx1_Fehler)}, range raw 0..1, transfer-property=PENDING, to Klima(timeout 3.5 s)  # Checksummenfehler
            signal DTS2_R744_ResponseError_XIX_DTS2s_R744_01_XIX_Klima_LIN6: start 38, 1 bit, little-endian, data-type-policy=OVERRIDE, i-signal-type=PRIMITIVE, init-value=0, base-type=BT_DTS2_R744_ResponseError, invalid-value=Invalid_DTS2_R744_ResponseError_XIX_DTS2s_R744_01_XIX_Klima_LIN6:1, compu {0=Cx0_kein_Fehler (CM_DTS2_R744_ResponseError_Cx0_kein_Fehler), 1=Cx1_Fehler (CM_DTS2_R744_ResponseError_Cx1_Fehler)}, range raw 0..1, transfer-property=PENDING, to Klima(timeout 3.5 s)  # siehe LIN2.0-Specification (Darf nicht über ein Fehlergueltigkeitsbit abgesichtert werden!)
            signal DTS2_R744_TNCTOC_XIX_DTS2s_R744_01_XIX_Klima_LIN6: start 39, 1 bit, little-endian, data-type-policy=OVERRIDE, i-signal-type=PRIMITIVE, init-value=1, base-type=BT_DTS2_R744_TNCTOC, compu {0=Cx0_DTC_test_completed_this_operation_cylce (CM_DTS2_R744_TNCTOC_Cx0_DTC_test_completed_this_operation_cylce), 1=Cx1_DTC_test_not_completed_this_operation_cylce (CM_DTS2_R744_TNCTOC_Cx1_DTC_test_not_completed_this_operation_cylce)}, range raw 0..1, transfer-property=PENDING, to Klima(timeout 3.5 s)  # testNotCompletedThisOperationCycle (TNCTOC)
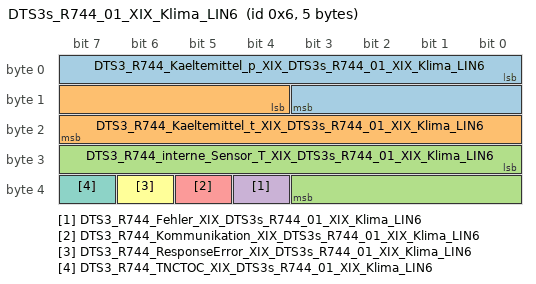
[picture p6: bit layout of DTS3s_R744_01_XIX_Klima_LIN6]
        frame DTS3s_R744_01_XIX_Klima_LIN6: id 0x6, to Klima, frame-length=5, lin-checksum=ENHANCED
          pdu DTS3s_R744_01_XIX_Klima_LIN6: length=5, unused-bit-pattern=0
            signal DTS3_R744_Kaeltemittel_p_XIX_DTS3s_R744_01_XIX_Klima_LIN6: start 0, 12 bit, little-endian, data-type-policy=OVERRIDE, i-signal-type=PRIMITIVE, init-value=4094, base-type=BT_DTS3_R744_Kaeltemittel_p, invalid-value=Invalid_DTS3_R744_Kaeltemittel_p_XIX_DTS3s_R744_01_XIX_Klima_LIN6:4095, compu {phys=raw*0.05 for raw 0..3400, 4094=Cxffe_Init (CM_DTS3_R744_Kaeltemittel_p_Cxffe_Init), 4095=Cxfff_Fehler (CM_DTS3_R744_Kaeltemittel_p_Cxfff_Fehler); unit Unit_Bar}, range phys 0..170 Unit_Bar, raw 0..4095, unit=Unit_Bar, transfer-property=PENDING, to Klima(timeout 3.5 s)  # Kaeltemitteldruck absolut
            signal DTS3_R744_Kaeltemittel_t_XIX_DTS3s_R744_01_XIX_Klima_LIN6: start 12, 12 bit, little-endian, data-type-policy=OVERRIDE, i-signal-type=PRIMITIVE, init-value=4094, base-type=BT_DTS3_R744_Kaeltemittel_t, invalid-value=Invalid_DTS3_R744_Kaeltemittel_t_XIX_DTS3s_R744_01_XIX_Klima_LIN6:4095, compu {phys=raw*0.1-40 for raw 0..2200, 4094=Cxffe_Init (CM_DTS3_R744_Kaeltemittel_t_Cxffe_Init), 4095=Cxfff_Fehler (CM_DTS3_R744_Kaeltemittel_t_Cxfff_Fehler); unit Unit_DegreCelsi}, range phys -40..180 Unit_DegreCelsi, raw 0..4095, unit=Unit_DegreCelsi, transfer-property=PENDING, to Klima(timeout 3.5 s)  # Kältemitteltemperatur
            signal DTS3_R744_interne_Sensor_T_XIX_DTS3s_R744_01_XIX_Klima_LIN6: start 24, 12 bit, little-endian, data-type-policy=OVERRIDE, i-signal-type=PRIMITIVE, init-value=4094, base-type=BT_DTS3_R744_interne_Sensor_T, invalid-value=Invalid_DTS3_R744_interne_Sensor_T_XIX_DTS3s_R744_01_XIX_Klima_LIN6:4095, compu {phys=raw*0.1-40 for raw 0..1800, 4094=Cxffe_Init (CM_DTS3_R744_interne_Sensor_T_Cxffe_Init), 4095=Cxfff_Fehler (CM_DTS3_R744_interne_Sensor_T_Cxfff_Fehler); unit Unit_DegreCelsi}, range phys -40..140 Unit_DegreCelsi, raw 0..4095, unit=Unit_DegreCelsi, transfer-property=PENDING, to Klima(timeout 3.5 s)  # interne Sensor-Temperatur
            signal DTS3_R744_Fehler_XIX_DTS3s_R744_01_XIX_Klima_LIN6: start 36, 1 bit, little-endian, data-type-policy=OVERRIDE, i-signal-type=PRIMITIVE, init-value=0, base-type=BT_DTS3_R744_Fehler, invalid-value=Invalid_DTS3_R744_Fehler_XIX_DTS3s_R744_01_XIX_Klima_LIN6:1, compu {0=Cx0_kein_Fehler (CM_DTS3_R744_Fehler_Cx0_kein_Fehler), 1=Cx1_Fehler (CM_DTS3_R744_Fehler_Cx1_Fehler)}, range raw 0..1, transfer-property=PENDING, to Klima(timeout 3.5 s)  # Interner Sensorfehler
            signal DTS3_R744_Kommunikation_XIX_DTS3s_R744_01_XIX_Klima_LIN6: start 37, 1 bit, little-endian, data-type-policy=OVERRIDE, i-signal-type=PRIMITIVE, init-value=0, base-type=BT_DTS3_R744_Kommunikation, invalid-value=Invalid_DTS3_R744_Kommunikation_XIX_DTS3s_R744_01_XIX_Klima_LIN6:1, compu {0=Cx0_kein_Fehler (CM_DTS3_R744_Kommunikation_Cx0_kein_Fehler), 1=Cx1_Fehler (CM_DTS3_R744_Kommunikation_Cx1_Fehler)}, range raw 0..1, transfer-property=PENDING, to Klima(timeout 3.5 s)  # Checksummenfehler
            signal DTS3_R744_ResponseError_XIX_DTS3s_R744_01_XIX_Klima_LIN6: start 38, 1 bit, little-endian, data-type-policy=OVERRIDE, i-signal-type=PRIMITIVE, init-value=0, base-type=BT_DTS3_R744_ResponseError, invalid-value=Invalid_DTS3_R744_ResponseError_XIX_DTS3s_R744_01_XIX_Klima_LIN6:1, compu {0=Cx0_kein_Fehler (CM_DTS3_R744_ResponseError_Cx0_kein_Fehler), 1=Cx1_Fehler (CM_DTS3_R744_ResponseError_Cx1_Fehler)}, range raw 0..1, transfer-property=PENDING, to Klima(timeout 3.5 s)  # siehe LIN2.0-Specification (Darf nicht über ein Fehlergueltigkeitsbit abgesichtert werden!)
            signal DTS3_R744_TNCTOC_XIX_DTS3s_R744_01_XIX_Klima_LIN6: start 39, 1 bit, little-endian, data-type-policy=OVERRIDE, i-signal-type=PRIMITIVE, init-value=1, base-type=BT_DTS3_R744_TNCTOC, compu {0=Cx0_DTC_test_completed_this_operation_cylce (CM_DTS3_R744_TNCTOC_Cx0_DTC_test_completed_this_operation_cylce), 1=Cx1_DTC_test_not_completed_this_operation_cylce (CM_DTS3_R744_TNCTOC_Cx1_DTC_test_not_completed_this_operation_cylce)}, range raw 0..1, transfer-property=PENDING, to Klima(timeout 3.5 s)  # testNotCompletedThisOperationCycle (TNCTOC)
        frame EASV1s_01_Status_XIX_Klima_LIN6: id 0x29, to Klima, frame-length=8, lin-checksum=ENHANCED
          pdu EASV1s_01_Status_XIX_Klima_LIN6: length=8, unused-bit-pattern=0
            signal EASV1_Ist_Position_Aktuator_XIX_EASV1s_01_Status_XIX_Klima_LIN6: start 0, 16 bit, little-endian, data-type-policy=OVERRIDE, i-signal-type=PRIMITIVE, init-value=65534, base-type=BT_EASV1_Ist_Position_Aktuator, invalid-value=Invalid_EASV1_Ist_Position_Aktuator_XIX_EASV1s_01_Status_XIX_Klima_LIN6:65535, compu {phys=raw for raw 0..65533, 65534=Cxfffe_Init (CM_EASV1_Ist_Position_Aktuator_Cxfffe_Init), 65535=Cxffff_Fehler (CM_EASV1_Ist_Position_Aktuator_Cxffff_Fehler); unit Unit_None}, range phys 0..65533 Unit_None, raw 0..65535, unit=Unit_None, transfer-property=PENDING, to Klima(timeout 3.5 s)  # Statusbotschaft für die elektrischen Kältemittelabsperrventile
            signal EASV1_Geschwindigkeitsstatus_XIX_EASV1s_01_Status_XIX_Klima_LIN6: start 16, 4 bit, little-endian, data-type-policy=OVERRIDE, i-signal-type=PRIMITIVE, base-type=BT_EASV1_Geschwindigkeitsstatus, invalid-value=Invalid_EASV1_Geschwindigkeitsstatus_XIX_EASV1s_01_Status_XIX_Klima_LIN6:15, compu {0=Cx0_Motor_steht (CM_EASV1_Geschwindigkeitsstatus_Cx0_Motor_steht), 1=Cx1_Geschwindigkeitsstufe_1 (CM_EASV1_Geschwindigkeitsstatus_Cx1_Geschwindigkeitsstufe_1), 2=Cx2_Geschwindigkeitsstufe_2 (CM_EASV1_Geschwindigkeitsstatus_Cx2_Geschwindigkeitsstufe_2), 3=Cx3_Geschwindigkeitsstufe_3 (CM_EASV1_Geschwindigkeitsstatus_Cx3_Geschwindigkeitsstufe_3), 4=Cx4_Geschwindigkeitsstufe_4 (CM_EASV1_Geschwindigkeitsstatus_Cx4_Geschwindigkeitsstufe_4), 5=Cx5_Autospeed (CM_EASV1_Geschwindigkeitsstatus_Cx5_Autospeed), 15=Cxf_Fehler (CM_EASV1_Geschwindigkeitsstatus_Cxf_Fehler)}, range raw 0..15, transfer-property=PENDING, to Klima(timeout 3.5 s)  # Statusbotschaft für die elektrischen Kältemittelabsperrventile
            signal EASV1_Temp_Warning_XIX_EASV1s_01_Status_XIX_Klima_LIN6: start 20, 1 bit, little-endian, data-type-policy=OVERRIDE, i-signal-type=PRIMITIVE, base-type=BT_EASV1_Temp_Warning, compu {0=Cx0_keine_Warnschwelle (CM_EASV1_Temp_Warning_Cx0_keine_Warnschwelle), 1=Cx1_Warnschwelle_erreicht (CM_EASV1_Temp_Warning_Cx1_Warnschwelle_erreicht)}, range raw 0..1, transfer-property=PENDING, to Klima(timeout 3.5 s)  # Statusbotschaft für die elektrischen Kältemittelabsperrventile
            signal EASV1_Temp_XIX_EASV1s_01_Status_XIX_Klima_LIN6: start 24, 8 bit, little-endian, data-type-policy=OVERRIDE, i-signal-type=PRIMITIVE, init-value=254, base-type=BT_EASV1_Temp, invalid-value=Invalid_EASV1_Temp_XIX_EASV1s_01_Status_XIX_Klima_LIN6:255, compu {phys=raw-50 for raw 0..253, 254=Cxfe_Init (CM_EASV1_Temp_Cxfe_Init), 255=Cxff_Fehler (CM_EASV1_Temp_Cxff_Fehler); unit Unit_DegreCelsi}, range phys -50..203 Unit_DegreCelsi, raw 0..255, unit=Unit_DegreCelsi, transfer-property=PENDING, to Klima(timeout 3.5 s)  # Platinentemperatur, Statusbotschaft für die elektrischen Kältemittelabsperrventile
            signal EASV1_Spulenbestromung_XIX_EASV1s_01_Status_XIX_Klima_LIN6: start 32, 2 bit, little-endian, data-type-policy=OVERRIDE, i-signal-type=PRIMITIVE, base-type=BT_EASV1_Spulenbestromung, invalid-value=Invalid_EASV1_Spulenbestromung_XIX_EASV1s_01_Status_XIX_Klima_LIN6:3, compu {0=Cx0_Motorspulen_unbestromt (CM_EASV1_Spulenbestromung_Cx0_Motorspulen_unbestromt), 1=Cx1_Motorspulen_bestromt (CM_EASV1_Spulenbestromung_Cx1_Motorspulen_bestromt), 2=Cx2_reserviert (CM_EASV1_Spulenbestromung_Cx2_reserviert), 3=Cx3_Fehler (CM_EASV1_Spulenbestromung_Cx3_Fehler)}, range raw 0..3, transfer-property=PENDING, to Klima(timeout 3.5 s)  # Statusbotschaft für die elektrischen Kältemittelabsperrventile
            signal EASV1_ErrMem_State_XIX_EASV1s_01_Status_XIX_Klima_LIN6: start 38, 2 bit, little-endian, data-type-policy=OVERRIDE, i-signal-type=PRIMITIVE, init-value=2, base-type=BT_EASV1_ErrMem_State, compu {1=Cx1_ErrMem_Active (CM_EASV1_ErrMem_State_Cx1_ErrMem_Active), 2=Cx2_ErrMem_Init_Progress (CM_EASV1_ErrMem_State_Cx2_ErrMem_Init_Progress), 3=Cx3_ErrMem_Init_Done (CM_EASV1_ErrMem_State_Cx3_ErrMem_Init_Done)}, range raw 1..3, transfer-property=PENDING, to Klima(timeout 3.5 s)  # Error Memory State
            signal EASV1_ResponseError_XIX_EASV1s_01_Status_XIX_Klima_LIN6: start 40, 1 bit, little-endian, data-type-policy=OVERRIDE, i-signal-type=PRIMITIVE, init-value=0, base-type=BT_EASV1_ResponseError, invalid-value=Invalid_EASV1_ResponseError_XIX_EASV1s_01_Status_XIX_Klima_LIN6:1, compu {0=Cx0_normal (CM_EASV1_ResponseError_Cx0_normal), 1=Cx1_Fehler (CM_EASV1_ResponseError_Cx1_Fehler)}, range raw 0..1, transfer-property=PENDING, to Klima(timeout 3.5 s)  # siehe LIN2.0-Specification (Darf nicht über ein Fehlergueltigkeitsbit abgesichtert werden!)
            signal EASV1_ResponseError_TNCTOC_XIX_EASV1s_01_Status_XIX_Klima_LIN6: start 41, 1 bit, little-endian, data-type-policy=OVERRIDE, i-signal-type=PRIMITIVE, init-value=1, base-type=BT_EASV1_ResponseError_TNCTOC, compu {0=Cx0_DTC_test_completed_this_operation_cylce (CM_EASV1_ResponseError_TNCTOC_Cx0_DTC_test_completed_this_operation_cylce), 1=Cx1_DTC_test_not_completed_this_operation_cylce (CM_EASV1_ResponseError_TNCTOC_Cx1_DTC_test_not_completed_this_operation_cylce)}, range raw 0..1, transfer-property=PENDING, to Klima(timeout 3.5 s)  # OBD TestFailed Flag, Statusbotschaft für die elektrischen Kältemittelexpansionsventile
            signal EASV1_Err_EDefekt_MoKomp_TF_XIX_EASV1s_01_Status_XIX_Klima_LIN6: start 42, 1 bit, little-endian, data-type-policy=OVERRIDE, i-signal-type=PRIMITIVE, base-type=BT_EASV1_Err_EDefekt_MoKomp_TF, compu {0=Cx0_passive (CM_EASV1_Err_EDefekt_MoKomp_TF_Cx0_passive), 1=Cx1_active (CM_EASV1_Err_EDefekt_MoKomp_TF_Cx1_active)}, range raw 0..1, transfer-property=PENDING, to Klima(timeout 3.5 s)  # OBD TestFailed Flag, Statusbotschaft für die elektrischen Kältemittelexpansionsventile
            signal EASV1_Err_EDefekt_MoKomp_TNCTOC_XIX_EASV1s_01_Status_XIX_Klima_LIN6: start 43, 1 bit, little-endian, data-type-policy=OVERRIDE, i-signal-type=PRIMITIVE, init-value=1, base-type=BT_EASV1_Err_EDefekt_MoKomp_TNCTOC, compu {0=Cx0_DTC_test_completed_this_operation_cylce (CM_EASV1_Err_EDefekt_MoKomp_TNCTOC_Cx0_DTC_test_completed_this_operation_cylce), 1=Cx1_DTC_test_not_completed_this_operation_cylce (CM_EASV1_Err_EDefekt_MoKomp_TNCTOC_Cx1_DTC_test_not_completed_this_operation_cylce)}, range raw 0..1, transfer-property=PENDING, to Klima(timeout 3.5 s)  # OBD TestFailed Flag, Statusbotschaft für die elektrischen Kältemittelexpansionsventile
            signal EASV1_Err_EDefekt_TSens_TF_XIX_EASV1s_01_Status_XIX_Klima_LIN6: start 44, 1 bit, little-endian, data-type-policy=OVERRIDE, i-signal-type=PRIMITIVE, base-type=BT_EASV1_Err_EDefekt_TSens_TF, compu {0=Cx0_passive (CM_EASV1_Err_EDefekt_TSens_TF_Cx0_passive), 1=Cx1_active (CM_EASV1_Err_EDefekt_TSens_TF_Cx1_active)}, range raw 0..1, transfer-property=PENDING, to Klima(timeout 3.5 s)  # OBD TestFailed Flag, Statusbotschaft für die elektrischen Kältemittelexpansionsventile
            signal EASV1_Err_EDefekt_TSens_TNCTOC_XIX_EASV1s_01_Status_XIX_Klima_LIN6: start 45, 1 bit, little-endian, data-type-policy=OVERRIDE, i-signal-type=PRIMITIVE, init-value=1, base-type=BT_EASV1_Err_EDefekt_TSens_TNCTOC, compu {0=Cx0_DTC_test_completed_this_operation_cylce (CM_EASV1_Err_EDefekt_TSens_TNCTOC_Cx0_DTC_test_completed_this_operation_cylce), 1=Cx1_DTC_test_not_completed_this_operation_cylce (CM_EASV1_Err_EDefekt_TSens_TNCTOC_Cx1_DTC_test_not_completed_this_operation_cylce)}, range raw 0..1, transfer-property=PENDING, to Klima(timeout 3.5 s)  # OBD TestFailed Flag, Statusbotschaft für die elektrischen Kältemittelexpansionsventile
            signal EASV1_Err_Uebertemperatur_TF_XIX_EASV1s_01_Status_XIX_Klima_LIN6: start 46, 1 bit, little-endian, data-type-policy=OVERRIDE, i-signal-type=PRIMITIVE, base-type=BT_EASV1_Err_Uebertemperatur_TF, compu {0=Cx0_passive (CM_EASV1_Err_Uebertemperatur_TF_Cx0_passive), 1=Cx1_active (CM_EASV1_Err_Uebertemperatur_TF_Cx1_active)}, range raw 0..1, transfer-property=PENDING, to Klima(timeout 3.5 s)  # OBD TestFailed Flag, Statusbotschaft für die elektrischen Kältemittelabsperrventile
            signal EASV1_Err_Uebertemperatur_TNCTOC_XIX_EASV1s_01_Status_XIX_Klima_LIN6: start 47, 1 bit, little-endian, data-type-policy=OVERRIDE, i-signal-type=PRIMITIVE, init-value=1, base-type=BT_EASV1_Err_Uebertemperatur_TNCTOC, compu {0=Cx0_DTC_test_completed_this_operation_cylce (CM_EASV1_Err_Uebertemperatur_TNCTOC_Cx0_DTC_test_completed_this_operation_cylce), 1=Cx1_DTC_test_not_completed_this_operation_cylce (CM_EASV1_Err_Uebertemperatur_TNCTOC_Cx1_DTC_test_not_completed_this_operation_cylce)}, range raw 0..1, transfer-property=PENDING, to Klima(timeout 3.5 s)  # OBD TestFailed Flag, Statusbotschaft für die elektrischen Kältemittelexpansionsventile
            signal EASV1_Err_Ueberspannung_TF_XIX_EASV1s_01_Status_XIX_Klima_LIN6: start 48, 1 bit, little-endian, data-type-policy=OVERRIDE, i-signal-type=PRIMITIVE, base-type=BT_EASV1_Err_Ueberspannung_TF, compu {0=Cx0_passive (CM_EASV1_Err_Ueberspannung_TF_Cx0_passive), 1=Cx1_active (CM_EASV1_Err_Ueberspannung_TF_Cx1_active)}, range raw 0..1, transfer-property=PENDING, to Klima(timeout 3.5 s)  # OBD TestFailed Flag, Statusbotschaft für die elektrischen Kältemittelexpansionsventile
            signal EASV1_Err_Ueberspannung_TNCTOC_XIX_EASV1s_01_Status_XIX_Klima_LIN6: start 49, 1 bit, little-endian, data-type-policy=OVERRIDE, i-signal-type=PRIMITIVE, init-value=1, base-type=BT_EASV1_Err_Ueberspannung_TNCTOC, compu {0=Cx0_DTC_test_completed_this_operation_cylce (CM_EASV1_Err_Ueberspannung_TNCTOC_Cx0_DTC_test_completed_this_operation_cylce), 1=Cx1_DTC_test_not_completed_this_operation_cylce (CM_EASV1_Err_Ueberspannung_TNCTOC_Cx1_DTC_test_not_completed_this_operation_cylce)}, range raw 0..1, transfer-property=PENDING, to Klima(timeout 3.5 s)  # OBD TestFailed Flag, Statusbotschaft für die elektrischen Kältemittelexpansionsventile
            signal EASV1_Err_Unterspannung_TF_XIX_EASV1s_01_Status_XIX_Klima_LIN6: start 50, 1 bit, little-endian, data-type-policy=OVERRIDE, i-signal-type=PRIMITIVE, base-type=BT_EASV1_Err_Unterspannung_TF, compu {0=Cx0_passive (CM_EASV1_Err_Unterspannung_TF_Cx0_passive), 1=Cx1_active (CM_EASV1_Err_Unterspannung_TF_Cx1_active)}, range raw 0..1, transfer-property=PENDING, to Klima(timeout 3.5 s)  # OBD TestFailed Flag, Statusbotschaft für die elektrischen Kältemittelexpansionsventile
            signal EASV1_Err_Unterspannung_TNCTOC_XIX_EASV1s_01_Status_XIX_Klima_LIN6: start 51, 1 bit, little-endian, data-type-policy=OVERRIDE, i-signal-type=PRIMITIVE, init-value=1, base-type=BT_EASV1_Err_Unterspannung_TNCTOC, compu {0=Cx0_DTC_test_completed_this_operation_cylce (CM_EASV1_Err_Unterspannung_TNCTOC_Cx0_DTC_test_completed_this_operation_cylce), 1=Cx1_DTC_test_not_completed_this_operation_cylce (CM_EASV1_Err_Unterspannung_TNCTOC_Cx1_DTC_test_not_completed_this_operation_cylce)}, range raw 0..1, transfer-property=PENDING, to Klima(timeout 3.5 s)  # OBD TestFailed Flag, Statusbotschaft für die elektrischen Kältemittelexpansionsventile
            signal EASV1_Err_Blockierung_TF_XIX_EASV1s_01_Status_XIX_Klima_LIN6: start 52, 1 bit, little-endian, data-type-policy=OVERRIDE, i-signal-type=PRIMITIVE, base-type=BT_EASV1_Err_Blockierung_TF, compu {0=Cx0_passive (CM_EASV1_Err_Blockierung_TF_Cx0_passive), 1=Cx1_active (CM_EASV1_Err_Blockierung_TF_Cx1_active)}, range raw 0..1, transfer-property=PENDING, to Klima(timeout 3.5 s)  # OBD TestFailed Flag, Statusbotschaft für die elektrischen Kältemittelexpansionsventile
            signal EASV1_Err_Blockierung_TNCTOC_XIX_EASV1s_01_Status_XIX_Klima_LIN6: start 53, 1 bit, little-endian, data-type-policy=OVERRIDE, i-signal-type=PRIMITIVE, init-value=1, base-type=BT_EASV1_Err_Blockierung_TNCTOC, compu {0=Cx0_DTC_test_completed_this_operation_cylce (CM_EASV1_Err_Blockierung_TNCTOC_Cx0_DTC_test_completed_this_operation_cylce), 1=Cx1_DTC_test_not_completed_this_operation_cylce (CM_EASV1_Err_Blockierung_TNCTOC_Cx1_DTC_test_not_completed_this_operation_cylce)}, range raw 0..1, transfer-property=PENDING, to Klima(timeout 3.5 s)  # OBD TestFailed Flag, Statusbotschaft für die elektrischen Kältemittelexpansionsventile
            signal EASV1_Err_RAMROMNADChange_TF_XIX_EASV1s_01_Status_XIX_Klima_LIN6: start 54, 1 bit, little-endian, data-type-policy=OVERRIDE, i-signal-type=PRIMITIVE, base-type=BT_EASV1_Err_RAMROMNADChange_TF, compu {0=Cx0_passive (CM_EASV1_Err_RAMROMNADChange_TF_Cx0_passive), 1=Cx1_active (CM_EASV1_Err_RAMROMNADChange_TF_Cx1_active)}, range raw 0..1, transfer-property=PENDING, to Klima(timeout 3.5 s)  # OBD TestFailed Flag, Statusbotschaft für die elektrischen Kältemittelexpansionsventile
            signal EASV1_Err_RAMROMNADChange_TNCTOC_XIX_EASV1s_01_Status_XIX_Klima_LIN6: start 55, 1 bit, little-endian, data-type-policy=OVERRIDE, i-signal-type=PRIMITIVE, init-value=1, base-type=BT_EASV1_Err_RAMROMNADChange_TNCTOC, compu {0=Cx0_DTC_test_completed_this_operation_cylce (CM_EASV1_Err_RAMROMNADChange_TNCTOC_Cx0_DTC_test_completed_this_operation_cylce), 1=Cx1_DTC_test_not_completed_this_operation_cylce (CM_EASV1_Err_RAMROMNADChange_TNCTOC_Cx1_DTC_test_not_completed_this_operation_cylce)}, range raw 0..1, transfer-property=PENDING, to Klima(timeout 3.5 s)  # OBD TestFailed Flag, Statusbotschaft für die elektrischen Kältemittelexpansionsventile
            signal EASV1_Err_Notlaufpos_TF_XIX_EASV1s_01_Status_XIX_Klima_LIN6: start 56, 1 bit, little-endian, data-type-policy=OVERRIDE, i-signal-type=PRIMITIVE, base-type=BT_EASV1_Err_Notlaufpos_TF, compu {0=Cx0_passive (CM_EASV1_Err_Notlaufpos_TF_Cx0_passive), 1=Cx1_active (CM_EASV1_Err_Notlaufpos_TF_Cx1_active)}, range raw 0..1, transfer-property=PENDING, to Klima(timeout 3.5 s)  # OBD TestFailed Flag, Statusbotschaft für die elektrischen Kältemittelexpansionsventile
            signal EASV1_Err_Notlaufpos_TNCTOC_XIX_EASV1s_01_Status_XIX_Klima_LIN6: start 57, 1 bit, little-endian, data-type-policy=OVERRIDE, i-signal-type=PRIMITIVE, init-value=1, base-type=BT_EASV1_Err_Notlaufpos_TNCTOC, compu {0=Cx0_DTC_test_completed_this_operation_cylce (CM_EASV1_Err_Notlaufpos_TNCTOC_Cx0_DTC_test_completed_this_operation_cylce), 1=Cx1_DTC_test_not_completed_this_operation_cylce (CM_EASV1_Err_Notlaufpos_TNCTOC_Cx1_DTC_test_not_completed_this_operation_cylce)}, range raw 0..1, transfer-property=PENDING, to Klima(timeout 3.5 s)  # OBD TestFailed Flag, Statusbotschaft für die elektrischen Kältemittelexpansionsventile
        frame EASV2s_01_Status_XIX_Klima_LIN6: id 0x2A, to Klima, frame-length=8, lin-checksum=ENHANCED
          pdu EASV2s_01_Status_XIX_Klima_LIN6: length=8, unused-bit-pattern=0
            signal EASV2_Ist_Position_Aktuator_XIX_EASV2s_01_Status_XIX_Klima_LIN6: start 0, 16 bit, little-endian, data-type-policy=OVERRIDE, i-signal-type=PRIMITIVE, init-value=65534, base-type=BT_EASV2_Ist_Position_Aktuator, invalid-value=Invalid_EASV2_Ist_Position_Aktuator_XIX_EASV2s_01_Status_XIX_Klima_LIN6:65535, compu {phys=raw for raw 0..65533, 65534=Cxfffe_Init (CM_EASV2_Ist_Position_Aktuator_Cxfffe_Init), 65535=Cxffff_Fehler (CM_EASV2_Ist_Position_Aktuator_Cxffff_Fehler); unit Unit_None}, range phys 0..65533 Unit_None, raw 0..65535, unit=Unit_None, transfer-property=PENDING, to Klima(timeout 3.5 s)  # Statusbotschaft für die elektrischen Kältemittelabsperrventile
            signal EASV2_Geschwindigkeitsstatus_XIX_EASV2s_01_Status_XIX_Klima_LIN6: start 16, 4 bit, little-endian, data-type-policy=OVERRIDE, i-signal-type=PRIMITIVE, base-type=BT_EASV2_Geschwindigkeitsstatus, invalid-value=Invalid_EASV2_Geschwindigkeitsstatus_XIX_EASV2s_01_Status_XIX_Klima_LIN6:15, compu {0=Cx0_Motor_steht (CM_EASV2_Geschwindigkeitsstatus_Cx0_Motor_steht), 1=Cx1_Geschwindigkeitsstufe_1 (CM_EASV2_Geschwindigkeitsstatus_Cx1_Geschwindigkeitsstufe_1), 2=Cx2_Geschwindigkeitsstufe_2 (CM_EASV2_Geschwindigkeitsstatus_Cx2_Geschwindigkeitsstufe_2), 3=Cx3_Geschwindigkeitsstufe_3 (CM_EASV2_Geschwindigkeitsstatus_Cx3_Geschwindigkeitsstufe_3), 4=Cx4_Geschwindigkeitsstufe_4 (CM_EASV2_Geschwindigkeitsstatus_Cx4_Geschwindigkeitsstufe_4), 5=Cx5_Autospeed (CM_EASV2_Geschwindigkeitsstatus_Cx5_Autospeed), 15=Cxf_Fehler (CM_EASV2_Geschwindigkeitsstatus_Cxf_Fehler)}, range raw 0..15, transfer-property=PENDING, to Klima(timeout 3.5 s)  # Statusbotschaft für die elektrischen Kältemittelabsperrventile
            signal EASV2_Temp_Warning_XIX_EASV2s_01_Status_XIX_Klima_LIN6: start 20, 1 bit, little-endian, data-type-policy=OVERRIDE, i-signal-type=PRIMITIVE, base-type=BT_EASV2_Temp_Warning, compu {0=Cx0_keine_Warnschwelle (CM_EASV2_Temp_Warning_Cx0_keine_Warnschwelle), 1=Cx1_Warnschwelle_erreicht (CM_EASV2_Temp_Warning_Cx1_Warnschwelle_erreicht)}, range raw 0..1, transfer-property=PENDING, to Klima(timeout 3.5 s)  # Statusbotschaft für die elektrischen Kältemittelabsperrventile
            signal EASV2_Temp_XIX_EASV2s_01_Status_XIX_Klima_LIN6: start 24, 8 bit, little-endian, data-type-policy=OVERRIDE, i-signal-type=PRIMITIVE, init-value=254, base-type=BT_EASV2_Temp, invalid-value=Invalid_EASV2_Temp_XIX_EASV2s_01_Status_XIX_Klima_LIN6:255, compu {phys=raw-50 for raw 0..253, 254=Cxfe_Init (CM_EASV2_Temp_Cxfe_Init), 255=Cxff_Fehler (CM_EASV2_Temp_Cxff_Fehler); unit Unit_DegreCelsi}, range phys -50..203 Unit_DegreCelsi, raw 0..255, unit=Unit_DegreCelsi, transfer-property=PENDING, to Klima(timeout 3.5 s)  # Platinentemperatur, Statusbotschaft für die elektrischen Kältemittelabsperrventile
            signal EASV2_Spulenbestromung_XIX_EASV2s_01_Status_XIX_Klima_LIN6: start 32, 2 bit, little-endian, data-type-policy=OVERRIDE, i-signal-type=PRIMITIVE, base-type=BT_EASV2_Spulenbestromung, invalid-value=Invalid_EASV2_Spulenbestromung_XIX_EASV2s_01_Status_XIX_Klima_LIN6:3, compu {0=Cx0_Motorspulen_unbestromt (CM_EASV2_Spulenbestromung_Cx0_Motorspulen_unbestromt), 1=Cx1_Motorspulen_bestromt (CM_EASV2_Spulenbestromung_Cx1_Motorspulen_bestromt), 2=Cx2_reserviert (CM_EASV2_Spulenbestromung_Cx2_reserviert), 3=Cx3_Fehler (CM_EASV2_Spulenbestromung_Cx3_Fehler)}, range raw 0..3, transfer-property=PENDING, to Klima(timeout 3.5 s)  # Statusbotschaft für die elektrischen Kältemittelabsperrventile
            signal EASV2_ErrMem_State_XIX_EASV2s_01_Status_XIX_Klima_LIN6: start 38, 2 bit, little-endian, data-type-policy=OVERRIDE, i-signal-type=PRIMITIVE, init-value=2, base-type=BT_EASV2_ErrMem_State, compu {1=Cx1_ErrMem_Active (CM_EASV2_ErrMem_State_Cx1_ErrMem_Active), 2=Cx2_ErrMem_Init_Progress (CM_EASV2_ErrMem_State_Cx2_ErrMem_Init_Progress), 3=Cx3_ErrMem_Init_Done (CM_EASV2_ErrMem_State_Cx3_ErrMem_Init_Done)}, range raw 1..3, transfer-property=PENDING, to Klima(timeout 3.5 s)  # Error Memory State
            signal EASV2_ResponseError_XIX_EASV2s_01_Status_XIX_Klima_LIN6: start 40, 1 bit, little-endian, data-type-policy=OVERRIDE, i-signal-type=PRIMITIVE, init-value=0, base-type=BT_EASV2_ResponseError, invalid-value=Invalid_EASV2_ResponseError_XIX_EASV2s_01_Status_XIX_Klima_LIN6:1, compu {0=Cx0_normal (CM_EASV2_ResponseError_Cx0_normal), 1=Cx1_Fehler (CM_EASV2_ResponseError_Cx1_Fehler)}, range raw 0..1, transfer-property=PENDING, to Klima(timeout 3.5 s)  # siehe LIN2.0-Specification (Darf nicht über ein Fehlergueltigkeitsbit abgesichtert werden!)
            signal EASV2_ResponseError_TNCTOC_XIX_EASV2s_01_Status_XIX_Klima_LIN6: start 41, 1 bit, little-endian, data-type-policy=OVERRIDE, i-signal-type=PRIMITIVE, init-value=1, base-type=BT_EASV2_ResponseError_TNCTOC, compu {0=Cx0_DTC_test_completed_this_operation_cylce (CM_EASV2_ResponseError_TNCTOC_Cx0_DTC_test_completed_this_operation_cylce), 1=Cx1_DTC_test_not_completed_this_operation_cylce (CM_EASV2_ResponseError_TNCTOC_Cx1_DTC_test_not_completed_this_operation_cylce)}, range raw 0..1, transfer-property=PENDING, to Klima(timeout 3.5 s)  # OBD TestFailed Flag, Statusbotschaft für die elektrischen Kältemittelexpansionsventile
            signal EASV2_Err_EDefekt_MoKomp_TF_XIX_EASV2s_01_Status_XIX_Klima_LIN6: start 42, 1 bit, little-endian, data-type-policy=OVERRIDE, i-signal-type=PRIMITIVE, base-type=BT_EASV2_Err_EDefekt_MoKomp_TF, compu {0=Cx0_passive (CM_EASV2_Err_EDefekt_MoKomp_TF_Cx0_passive), 1=Cx1_active (CM_EASV2_Err_EDefekt_MoKomp_TF_Cx1_active)}, range raw 0..1, transfer-property=PENDING, to Klima(timeout 3.5 s)  # OBD TestFailed Flag, Statusbotschaft für die elektrischen Kältemittelexpansionsventile
            signal EASV2_Err_EDefekt_MoKomp_TNCTOC_XIX_EASV2s_01_Status_XIX_Klima_LIN6: start 43, 1 bit, little-endian, data-type-policy=OVERRIDE, i-signal-type=PRIMITIVE, init-value=1, base-type=BT_EASV2_Err_EDefekt_MoKomp_TNCTOC, compu {0=Cx0_DTC_test_completed_this_operation_cylce (CM_EASV2_Err_EDefekt_MoKomp_TNCTOC_Cx0_DTC_test_completed_this_operation_cylce), 1=Cx1_DTC_test_not_completed_this_operation_cylce (CM_EASV2_Err_EDefekt_MoKomp_TNCTOC_Cx1_DTC_test_not_completed_this_operation_cylce)}, range raw 0..1, transfer-property=PENDING, to Klima(timeout 3.5 s)  # OBD TestFailed Flag, Statusbotschaft für die elektrischen Kältemittelexpansionsventile
            signal EASV2_Err_EDefekt_TSens_TF_XIX_EASV2s_01_Status_XIX_Klima_LIN6: start 44, 1 bit, little-endian, data-type-policy=OVERRIDE, i-signal-type=PRIMITIVE, base-type=BT_EASV2_Err_EDefekt_TSens_TF, compu {0=Cx0_passive (CM_EASV2_Err_EDefekt_TSens_TF_Cx0_passive), 1=Cx1_active (CM_EASV2_Err_EDefekt_TSens_TF_Cx1_active)}, range raw 0..1, transfer-property=PENDING, to Klima(timeout 3.5 s)  # OBD TestFailed Flag, Statusbotschaft für die elektrischen Kältemittelexpansionsventile
            signal EASV2_Err_EDefekt_TSens_TNCTOC_XIX_EASV2s_01_Status_XIX_Klima_LIN6: start 45, 1 bit, little-endian, data-type-policy=OVERRIDE, i-signal-type=PRIMITIVE, init-value=1, base-type=BT_EASV2_Err_EDefekt_TSens_TNCTOC, compu {0=Cx0_DTC_test_completed_this_operation_cylce (CM_EASV2_Err_EDefekt_TSens_TNCTOC_Cx0_DTC_test_completed_this_operation_cylce), 1=Cx1_DTC_test_not_completed_this_operation_cylce (CM_EASV2_Err_EDefekt_TSens_TNCTOC_Cx1_DTC_test_not_completed_this_operation_cylce)}, range raw 0..1, transfer-property=PENDING, to Klima(timeout 3.5 s)  # OBD TestFailed Flag, Statusbotschaft für die elektrischen Kältemittelexpansionsventile
            signal EASV2_Err_Uebertemperatur_TF_XIX_EASV2s_01_Status_XIX_Klima_LIN6: start 46, 1 bit, little-endian, data-type-policy=OVERRIDE, i-signal-type=PRIMITIVE, base-type=BT_EASV2_Err_Uebertemperatur_TF, compu {0=Cx0_passive (CM_EASV2_Err_Uebertemperatur_TF_Cx0_passive), 1=Cx1_active (CM_EASV2_Err_Uebertemperatur_TF_Cx1_active)}, range raw 0..1, transfer-property=PENDING, to Klima(timeout 3.5 s)  # OBD TestFailed Flag, Statusbotschaft für die elektrischen Kältemittelabsperrventile
            signal EASV2_Err_Uebertemperatur_TNCTOC_XIX_EASV2s_01_Status_XIX_Klima_LIN6: start 47, 1 bit, little-endian, data-type-policy=OVERRIDE, i-signal-type=PRIMITIVE, init-value=1, base-type=BT_EASV2_Err_Uebertemperatur_TNCTOC, compu {0=Cx0_DTC_test_completed_this_operation_cylce (CM_EASV2_Err_Uebertemperatur_TNCTOC_Cx0_DTC_test_completed_this_operation_cylce), 1=Cx1_DTC_test_not_completed_this_operation_cylce (CM_EASV2_Err_Uebertemperatur_TNCTOC_Cx1_DTC_test_not_completed_this_operation_cylce)}, range raw 0..1, transfer-property=PENDING, to Klima(timeout 3.5 s)  # OBD TestFailed Flag, Statusbotschaft für die elektrischen Kältemittelexpansionsventile
            signal EASV2_Err_Ueberspannung_TF_XIX_EASV2s_01_Status_XIX_Klima_LIN6: start 48, 1 bit, little-endian, data-type-policy=OVERRIDE, i-signal-type=PRIMITIVE, base-type=BT_EASV2_Err_Ueberspannung_TF, compu {0=Cx0_passive (CM_EASV2_Err_Ueberspannung_TF_Cx0_passive), 1=Cx1_active (CM_EASV2_Err_Ueberspannung_TF_Cx1_active)}, range raw 0..1, transfer-property=PENDING, to Klima(timeout 3.5 s)  # OBD TestFailed Flag, Statusbotschaft für die elektrischen Kältemittelexpansionsventile
            signal EASV2_Err_Ueberspannung_TNCTOC_XIX_EASV2s_01_Status_XIX_Klima_LIN6: start 49, 1 bit, little-endian, data-type-policy=OVERRIDE, i-signal-type=PRIMITIVE, init-value=1, base-type=BT_EASV2_Err_Ueberspannung_TNCTOC, compu {0=Cx0_DTC_test_completed_this_operation_cylce (CM_EASV2_Err_Ueberspannung_TNCTOC_Cx0_DTC_test_completed_this_operation_cylce), 1=Cx1_DTC_test_not_completed_this_operation_cylce (CM_EASV2_Err_Ueberspannung_TNCTOC_Cx1_DTC_test_not_completed_this_operation_cylce)}, range raw 0..1, transfer-property=PENDING, to Klima(timeout 3.5 s)  # OBD TestFailed Flag, Statusbotschaft für die elektrischen Kältemittelexpansionsventile
            signal EASV2_Err_Unterspannung_TF_XIX_EASV2s_01_Status_XIX_Klima_LIN6: start 50, 1 bit, little-endian, data-type-policy=OVERRIDE, i-signal-type=PRIMITIVE, base-type=BT_EASV2_Err_Unterspannung_TF, compu {0=Cx0_passive (CM_EASV2_Err_Unterspannung_TF_Cx0_passive), 1=Cx1_active (CM_EASV2_Err_Unterspannung_TF_Cx1_active)}, range raw 0..1, transfer-property=PENDING, to Klima(timeout 3.5 s)  # OBD TestFailed Flag, Statusbotschaft für die elektrischen Kältemittelexpansionsventile
            signal EASV2_Err_Unterspannung_TNCTOC_XIX_EASV2s_01_Status_XIX_Klima_LIN6: start 51, 1 bit, little-endian, data-type-policy=OVERRIDE, i-signal-type=PRIMITIVE, init-value=1, base-type=BT_EASV2_Err_Unterspannung_TNCTOC, compu {0=Cx0_DTC_test_completed_this_operation_cylce (CM_EASV2_Err_Unterspannung_TNCTOC_Cx0_DTC_test_completed_this_operation_cylce), 1=Cx1_DTC_test_not_completed_this_operation_cylce (CM_EASV2_Err_Unterspannung_TNCTOC_Cx1_DTC_test_not_completed_this_operation_cylce)}, range raw 0..1, transfer-property=PENDING, to Klima(timeout 3.5 s)  # OBD TestFailed Flag, Statusbotschaft für die elektrischen Kältemittelexpansionsventile
            signal EASV2_Err_Blockierung_TF_XIX_EASV2s_01_Status_XIX_Klima_LIN6: start 52, 1 bit, little-endian, data-type-policy=OVERRIDE, i-signal-type=PRIMITIVE, base-type=BT_EASV2_Err_Blockierung_TF, compu {0=Cx0_passive (CM_EASV2_Err_Blockierung_TF_Cx0_passive), 1=Cx1_active (CM_EASV2_Err_Blockierung_TF_Cx1_active)}, range raw 0..1, transfer-property=PENDING, to Klima(timeout 3.5 s)  # OBD TestFailed Flag, Statusbotschaft für die elektrischen Kältemittelexpansionsventile
            signal EASV2_Err_Blockierung_TNCTOC_XIX_EASV2s_01_Status_XIX_Klima_LIN6: start 53, 1 bit, little-endian, data-type-policy=OVERRIDE, i-signal-type=PRIMITIVE, init-value=1, base-type=BT_EASV2_Err_Blockierung_TNCTOC, compu {0=Cx0_DTC_test_completed_this_operation_cylce (CM_EASV2_Err_Blockierung_TNCTOC_Cx0_DTC_test_completed_this_operation_cylce), 1=Cx1_DTC_test_not_completed_this_operation_cylce (CM_EASV2_Err_Blockierung_TNCTOC_Cx1_DTC_test_not_completed_this_operation_cylce)}, range raw 0..1, transfer-property=PENDING, to Klima(timeout 3.5 s)  # OBD TestFailed Flag, Statusbotschaft für die elektrischen Kältemittelexpansionsventile
            signal EASV2_Err_RAMROMNADChange_TF_XIX_EASV2s_01_Status_XIX_Klima_LIN6: start 54, 1 bit, little-endian, data-type-policy=OVERRIDE, i-signal-type=PRIMITIVE, base-type=BT_EASV2_Err_RAMROMNADChange_TF, compu {0=Cx0_passive (CM_EASV2_Err_RAMROMNADChange_TF_Cx0_passive), 1=Cx1_active (CM_EASV2_Err_RAMROMNADChange_TF_Cx1_active)}, range raw 0..1, transfer-property=PENDING, to Klima(timeout 3.5 s)  # OBD TestFailed Flag, Statusbotschaft für die elektrischen Kältemittelexpansionsventile
            signal EASV2_Err_RAMROMNADChange_TNCTOC_XIX_EASV2s_01_Status_XIX_Klima_LIN6: start 55, 1 bit, little-endian, data-type-policy=OVERRIDE, i-signal-type=PRIMITIVE, init-value=1, base-type=BT_EASV2_Err_RAMROMNADChange_TNCTOC, compu {0=Cx0_DTC_test_completed_this_operation_cylce (CM_EASV2_Err_RAMROMNADChange_TNCTOC_Cx0_DTC_test_completed_this_operation_cylce), 1=Cx1_DTC_test_not_completed_this_operation_cylce (CM_EASV2_Err_RAMROMNADChange_TNCTOC_Cx1_DTC_test_not_completed_this_operation_cylce)}, range raw 0..1, transfer-property=PENDING, to Klima(timeout 3.5 s)  # OBD TestFailed Flag, Statusbotschaft für die elektrischen Kältemittelexpansionsventile
            signal EASV2_Err_Notlaufpos_TF_XIX_EASV2s_01_Status_XIX_Klima_LIN6: start 56, 1 bit, little-endian, data-type-policy=OVERRIDE, i-signal-type=PRIMITIVE, base-type=BT_EASV2_Err_Notlaufpos_TF, compu {0=Cx0_passive (CM_EASV2_Err_Notlaufpos_TF_Cx0_passive), 1=Cx1_active (CM_EASV2_Err_Notlaufpos_TF_Cx1_active)}, range raw 0..1, transfer-property=PENDING, to Klima(timeout 3.5 s)  # OBD TestFailed Flag, Statusbotschaft für die elektrischen Kältemittelexpansionsventile
            signal EASV2_Err_Notlaufpos_TNCTOC_XIX_EASV2s_01_Status_XIX_Klima_LIN6: start 57, 1 bit, little-endian, data-type-policy=OVERRIDE, i-signal-type=PRIMITIVE, init-value=1, base-type=BT_EASV2_Err_Notlaufpos_TNCTOC, compu {0=Cx0_DTC_test_completed_this_operation_cylce (CM_EASV2_Err_Notlaufpos_TNCTOC_Cx0_DTC_test_completed_this_operation_cylce), 1=Cx1_DTC_test_not_completed_this_operation_cylce (CM_EASV2_Err_Notlaufpos_TNCTOC_Cx1_DTC_test_not_completed_this_operation_cylce)}, range raw 0..1, transfer-property=PENDING, to Klima(timeout 3.5 s)  # OBD TestFailed Flag, Statusbotschaft für die elektrischen Kältemittelexpansionsventile
        frame EASV3s_01_Status_XIX_Klima_LIN6: id 0x2B, to Klima, frame-length=8, lin-checksum=ENHANCED
          pdu EASV3s_01_Status_XIX_Klima_LIN6: length=8, unused-bit-pattern=0
            signal EASV3_Ist_Position_Aktuator_XIX_EASV3s_01_Status_XIX_Klima_LIN6: start 0, 16 bit, little-endian, data-type-policy=OVERRIDE, i-signal-type=PRIMITIVE, init-value=65534, base-type=BT_EASV3_Ist_Position_Aktuator, invalid-value=Invalid_EASV3_Ist_Position_Aktuator_XIX_EASV3s_01_Status_XIX_Klima_LIN6:65535, compu {phys=raw for raw 0..65533, 65534=Cxfffe_Init (CM_EASV3_Ist_Position_Aktuator_Cxfffe_Init), 65535=Cxffff_Fehler (CM_EASV3_Ist_Position_Aktuator_Cxffff_Fehler); unit Unit_None}, range phys 0..65533 Unit_None, raw 0..65535, unit=Unit_None, transfer-property=PENDING, to Klima(timeout 3.5 s)  # Statusbotschaft für die elektrischen Kältemittelabsperrventile
            signal EASV3_Geschwindigkeitsstatus_XIX_EASV3s_01_Status_XIX_Klima_LIN6: start 16, 4 bit, little-endian, data-type-policy=OVERRIDE, i-signal-type=PRIMITIVE, base-type=BT_EASV3_Geschwindigkeitsstatus, invalid-value=Invalid_EASV3_Geschwindigkeitsstatus_XIX_EASV3s_01_Status_XIX_Klima_LIN6:15, compu {0=Cx0_Motor_steht (CM_EASV3_Geschwindigkeitsstatus_Cx0_Motor_steht), 1=Cx1_Geschwindigkeitsstufe_1 (CM_EASV3_Geschwindigkeitsstatus_Cx1_Geschwindigkeitsstufe_1), 2=Cx2_Geschwindigkeitsstufe_2 (CM_EASV3_Geschwindigkeitsstatus_Cx2_Geschwindigkeitsstufe_2), 3=Cx3_Geschwindigkeitsstufe_3 (CM_EASV3_Geschwindigkeitsstatus_Cx3_Geschwindigkeitsstufe_3), 4=Cx4_Geschwindigkeitsstufe_4 (CM_EASV3_Geschwindigkeitsstatus_Cx4_Geschwindigkeitsstufe_4), 5=Cx5_Autospeed (CM_EASV3_Geschwindigkeitsstatus_Cx5_Autospeed), 15=Cxf_Fehler (CM_EASV3_Geschwindigkeitsstatus_Cxf_Fehler)}, range raw 0..15, transfer-property=PENDING, to Klima(timeout 3.5 s)  # Statusbotschaft für die elektrischen Kältemittelabsperrventile
            signal EASV3_Temp_Warning_XIX_EASV3s_01_Status_XIX_Klima_LIN6: start 20, 1 bit, little-endian, data-type-policy=OVERRIDE, i-signal-type=PRIMITIVE, base-type=BT_EASV3_Temp_Warning, compu {0=Cx0_keine_Warnschwelle (CM_EASV3_Temp_Warning_Cx0_keine_Warnschwelle), 1=Cx1_Warnschwelle_erreicht (CM_EASV3_Temp_Warning_Cx1_Warnschwelle_erreicht)}, range raw 0..1, transfer-property=PENDING, to Klima(timeout 3.5 s)  # Statusbotschaft für die elektrischen Kältemittelabsperrventile
            signal EASV3_Temp_XIX_EASV3s_01_Status_XIX_Klima_LIN6: start 24, 8 bit, little-endian, data-type-policy=OVERRIDE, i-signal-type=PRIMITIVE, init-value=254, base-type=BT_EASV3_Temp, invalid-value=Invalid_EASV3_Temp_XIX_EASV3s_01_Status_XIX_Klima_LIN6:255, compu {phys=raw-50 for raw 0..253, 254=Cxfe_Init (CM_EASV3_Temp_Cxfe_Init), 255=Cxff_Fehler (CM_EASV3_Temp_Cxff_Fehler); unit Unit_DegreCelsi}, range phys -50..203 Unit_DegreCelsi, raw 0..255, unit=Unit_DegreCelsi, transfer-property=PENDING, to Klima(timeout 3.5 s)  # Platinentemperatur, Statusbotschaft für die elektrischen Kältemittelabsperrventile
            signal EASV3_Spulenbestromung_XIX_EASV3s_01_Status_XIX_Klima_LIN6: start 32, 2 bit, little-endian, data-type-policy=OVERRIDE, i-signal-type=PRIMITIVE, base-type=BT_EASV3_Spulenbestromung, invalid-value=Invalid_EASV3_Spulenbestromung_XIX_EASV3s_01_Status_XIX_Klima_LIN6:3, compu {0=Cx0_Motorspulen_unbestromt (CM_EASV3_Spulenbestromung_Cx0_Motorspulen_unbestromt), 1=Cx1_Motorspulen_bestromt (CM_EASV3_Spulenbestromung_Cx1_Motorspulen_bestromt), 2=Cx2_reserviert (CM_EASV3_Spulenbestromung_Cx2_reserviert), 3=Cx3_Fehler (CM_EASV3_Spulenbestromung_Cx3_Fehler)}, range raw 0..3, transfer-property=PENDING, to Klima(timeout 3.5 s)  # Statusbotschaft für die elektrischen Kältemittelabsperrventile
            signal EASV3_ErrMem_State_XIX_EASV3s_01_Status_XIX_Klima_LIN6: start 38, 2 bit, little-endian, data-type-policy=OVERRIDE, i-signal-type=PRIMITIVE, init-value=2, base-type=BT_EASV3_ErrMem_State, compu {1=Cx1_ErrMem_Active (CM_EASV3_ErrMem_State_Cx1_ErrMem_Active), 2=Cx2_ErrMem_Init_Progress (CM_EASV3_ErrMem_State_Cx2_ErrMem_Init_Progress), 3=Cx3_ErrMem_Init_Done (CM_EASV3_ErrMem_State_Cx3_ErrMem_Init_Done)}, range raw 1..3, transfer-property=PENDING, to Klima(timeout 3.5 s)  # Error Memory State
            signal EASV3_ResponseError_XIX_EASV3s_01_Status_XIX_Klima_LIN6: start 40, 1 bit, little-endian, data-type-policy=OVERRIDE, i-signal-type=PRIMITIVE, init-value=0, base-type=BT_EASV3_ResponseError, invalid-value=Invalid_EASV3_ResponseError_XIX_EASV3s_01_Status_XIX_Klima_LIN6:1, compu {0=Cx0_normal (CM_EASV3_ResponseError_Cx0_normal), 1=Cx1_Fehler (CM_EASV3_ResponseError_Cx1_Fehler)}, range raw 0..1, transfer-property=PENDING, to Klima(timeout 3.5 s)  # siehe LIN2.0-Specification (Darf nicht über ein Fehlergueltigkeitsbit abgesichtert werden!)
            signal EASV3_ResponseError_TNCTOC_XIX_EASV3s_01_Status_XIX_Klima_LIN6: start 41, 1 bit, little-endian, data-type-policy=OVERRIDE, i-signal-type=PRIMITIVE, init-value=1, base-type=BT_EASV3_ResponseError_TNCTOC, compu {0=Cx0_DTC_test_completed_this_operation_cylce (CM_EASV3_ResponseError_TNCTOC_Cx0_DTC_test_completed_this_operation_cylce), 1=Cx1_DTC_test_not_completed_this_operation_cylce (CM_EASV3_ResponseError_TNCTOC_Cx1_DTC_test_not_completed_this_operation_cylce)}, range raw 0..1, transfer-property=PENDING, to Klima(timeout 3.5 s)  # OBD TestFailed Flag, Statusbotschaft für die elektrischen Kältemittelexpansionsventile
            signal EASV3_Err_EDefekt_MoKomp_TF_XIX_EASV3s_01_Status_XIX_Klima_LIN6: start 42, 1 bit, little-endian, data-type-policy=OVERRIDE, i-signal-type=PRIMITIVE, base-type=BT_EASV3_Err_EDefekt_MoKomp_TF, compu {0=Cx0_passive (CM_EASV3_Err_EDefekt_MoKomp_TF_Cx0_passive), 1=Cx1_active (CM_EASV3_Err_EDefekt_MoKomp_TF_Cx1_active)}, range raw 0..1, transfer-property=PENDING, to Klima(timeout 3.5 s)  # OBD TestFailed Flag, Statusbotschaft für die elektrischen Kältemittelexpansionsventile
            signal EASV3_Err_EDefekt_MoKomp_TNCTOC_XIX_EASV3s_01_Status_XIX_Klima_LIN6: start 43, 1 bit, little-endian, data-type-policy=OVERRIDE, i-signal-type=PRIMITIVE, init-value=1, base-type=BT_EASV3_Err_EDefekt_MoKomp_TNCTOC, compu {0=Cx0_DTC_test_completed_this_operation_cylce (CM_EASV3_Err_EDefekt_MoKomp_TNCTOC_Cx0_DTC_test_completed_this_operation_cylce), 1=Cx1_DTC_test_not_completed_this_operation_cylce (CM_EASV3_Err_EDefekt_MoKomp_TNCTOC_Cx1_DTC_test_not_completed_this_operation_cylce)}, range raw 0..1, transfer-property=PENDING, to Klima(timeout 3.5 s)  # OBD TestFailed Flag, Statusbotschaft für die elektrischen Kältemittelexpansionsventile
            signal EASV3_Err_EDefekt_TSens_TF_XIX_EASV3s_01_Status_XIX_Klima_LIN6: start 44, 1 bit, little-endian, data-type-policy=OVERRIDE, i-signal-type=PRIMITIVE, base-type=BT_EASV3_Err_EDefekt_TSens_TF, compu {0=Cx0_passive (CM_EASV3_Err_EDefekt_TSens_TF_Cx0_passive), 1=Cx1_active (CM_EASV3_Err_EDefekt_TSens_TF_Cx1_active)}, range raw 0..1, transfer-property=PENDING, to Klima(timeout 3.5 s)  # OBD TestFailed Flag, Statusbotschaft für die elektrischen Kältemittelexpansionsventile
            signal EASV3_Err_EDefekt_TSens_TNCTOC_XIX_EASV3s_01_Status_XIX_Klima_LIN6: start 45, 1 bit, little-endian, data-type-policy=OVERRIDE, i-signal-type=PRIMITIVE, init-value=1, base-type=BT_EASV3_Err_EDefekt_TSens_TNCTOC, compu {0=Cx0_DTC_test_completed_this_operation_cylce (CM_EASV3_Err_EDefekt_TSens_TNCTOC_Cx0_DTC_test_completed_this_operation_cylce), 1=Cx1_DTC_test_not_completed_this_operation_cylce (CM_EASV3_Err_EDefekt_TSens_TNCTOC_Cx1_DTC_test_not_completed_this_operation_cylce)}, range raw 0..1, transfer-property=PENDING, to Klima(timeout 3.5 s)  # OBD TestFailed Flag, Statusbotschaft für die elektrischen Kältemittelexpansionsventile
            signal EASV3_Err_Uebertemperatur_TF_XIX_EASV3s_01_Status_XIX_Klima_LIN6: start 46, 1 bit, little-endian, data-type-policy=OVERRIDE, i-signal-type=PRIMITIVE, base-type=BT_EASV3_Err_Uebertemperatur_TF, compu {0=Cx0_passive (CM_EASV3_Err_Uebertemperatur_TF_Cx0_passive), 1=Cx1_active (CM_EASV3_Err_Uebertemperatur_TF_Cx1_active)}, range raw 0..1, transfer-property=PENDING, to Klima(timeout 3.5 s)  # OBD TestFailed Flag, Statusbotschaft für die elektrischen Kältemittelabsperrventile
            signal EASV3_Err_Uebertemperatur_TNCTOC_XIX_EASV3s_01_Status_XIX_Klima_LIN6: start 47, 1 bit, little-endian, data-type-policy=OVERRIDE, i-signal-type=PRIMITIVE, init-value=1, base-type=BT_EASV3_Err_Uebertemperatur_TNCTOC, compu {0=Cx0_DTC_test_completed_this_operation_cylce (CM_EASV3_Err_Uebertemperatur_TNCTOC_Cx0_DTC_test_completed_this_operation_cylce), 1=Cx1_DTC_test_not_completed_this_operation_cylce (CM_EASV3_Err_Uebertemperatur_TNCTOC_Cx1_DTC_test_not_completed_this_operation_cylce)}, range raw 0..1, transfer-property=PENDING, to Klima(timeout 3.5 s)  # OBD TestFailed Flag, Statusbotschaft für die elektrischen Kältemittelexpansionsventile
            signal EASV3_Err_Ueberspannung_TF_XIX_EASV3s_01_Status_XIX_Klima_LIN6: start 48, 1 bit, little-endian, data-type-policy=OVERRIDE, i-signal-type=PRIMITIVE, base-type=BT_EASV3_Err_Ueberspannung_TF, compu {0=Cx0_passive (CM_EASV3_Err_Ueberspannung_TF_Cx0_passive), 1=Cx1_active (CM_EASV3_Err_Ueberspannung_TF_Cx1_active)}, range raw 0..1, transfer-property=PENDING, to Klima(timeout 3.5 s)  # OBD TestFailed Flag, Statusbotschaft für die elektrischen Kältemittelexpansionsventile
            signal EASV3_Err_Ueberspannung_TNCTOC_XIX_EASV3s_01_Status_XIX_Klima_LIN6: start 49, 1 bit, little-endian, data-type-policy=OVERRIDE, i-signal-type=PRIMITIVE, init-value=1, base-type=BT_EASV3_Err_Ueberspannung_TNCTOC, compu {0=Cx0_DTC_test_completed_this_operation_cylce (CM_EASV3_Err_Ueberspannung_TNCTOC_Cx0_DTC_test_completed_this_operation_cylce), 1=Cx1_DTC_test_not_completed_this_operation_cylce (CM_EASV3_Err_Ueberspannung_TNCTOC_Cx1_DTC_test_not_completed_this_operation_cylce)}, range raw 0..1, transfer-property=PENDING, to Klima(timeout 3.5 s)  # OBD TestFailed Flag, Statusbotschaft für die elektrischen Kältemittelexpansionsventile
            signal EASV3_Err_Unterspannung_TF_XIX_EASV3s_01_Status_XIX_Klima_LIN6: start 50, 1 bit, little-endian, data-type-policy=OVERRIDE, i-signal-type=PRIMITIVE, base-type=BT_EASV3_Err_Unterspannung_TF, compu {0=Cx0_passive (CM_EASV3_Err_Unterspannung_TF_Cx0_passive), 1=Cx1_active (CM_EASV3_Err_Unterspannung_TF_Cx1_active)}, range raw 0..1, transfer-property=PENDING, to Klima(timeout 3.5 s)  # OBD TestFailed Flag, Statusbotschaft für die elektrischen Kältemittelexpansionsventile
            signal EASV3_Err_Unterspannung_TNCTOC_XIX_EASV3s_01_Status_XIX_Klima_LIN6: start 51, 1 bit, little-endian, data-type-policy=OVERRIDE, i-signal-type=PRIMITIVE, init-value=1, base-type=BT_EASV3_Err_Unterspannung_TNCTOC, compu {0=Cx0_DTC_test_completed_this_operation_cylce (CM_EASV3_Err_Unterspannung_TNCTOC_Cx0_DTC_test_completed_this_operation_cylce), 1=Cx1_DTC_test_not_completed_this_operation_cylce (CM_EASV3_Err_Unterspannung_TNCTOC_Cx1_DTC_test_not_completed_this_operation_cylce)}, range raw 0..1, transfer-property=PENDING, to Klima(timeout 3.5 s)  # OBD TestFailed Flag, Statusbotschaft für die elektrischen Kältemittelexpansionsventile
            signal EASV3_Err_Blockierung_TF_XIX_EASV3s_01_Status_XIX_Klima_LIN6: start 52, 1 bit, little-endian, data-type-policy=OVERRIDE, i-signal-type=PRIMITIVE, base-type=BT_EASV3_Err_Blockierung_TF, compu {0=Cx0_passive (CM_EASV3_Err_Blockierung_TF_Cx0_passive), 1=Cx1_active (CM_EASV3_Err_Blockierung_TF_Cx1_active)}, range raw 0..1, transfer-property=PENDING, to Klima(timeout 3.5 s)  # OBD TestFailed Flag, Statusbotschaft für die elektrischen Kältemittelexpansionsventile
            signal EASV3_Err_Blockierung_TNCTOC_XIX_EASV3s_01_Status_XIX_Klima_LIN6: start 53, 1 bit, little-endian, data-type-policy=OVERRIDE, i-signal-type=PRIMITIVE, init-value=1, base-type=BT_EASV3_Err_Blockierung_TNCTOC, compu {0=Cx0_DTC_test_completed_this_operation_cylce (CM_EASV3_Err_Blockierung_TNCTOC_Cx0_DTC_test_completed_this_operation_cylce), 1=Cx1_DTC_test_not_completed_this_operation_cylce (CM_EASV3_Err_Blockierung_TNCTOC_Cx1_DTC_test_not_completed_this_operation_cylce)}, range raw 0..1, transfer-property=PENDING, to Klima(timeout 3.5 s)  # OBD TestFailed Flag, Statusbotschaft für die elektrischen Kältemittelexpansionsventile
            signal EASV3_Err_RAMROMNADChange_TF_XIX_EASV3s_01_Status_XIX_Klima_LIN6: start 54, 1 bit, little-endian, data-type-policy=OVERRIDE, i-signal-type=PRIMITIVE, base-type=BT_EASV3_Err_RAMROMNADChange_TF, compu {0=Cx0_passive (CM_EASV3_Err_RAMROMNADChange_TF_Cx0_passive), 1=Cx1_active (CM_EASV3_Err_RAMROMNADChange_TF_Cx1_active)}, range raw 0..1, transfer-property=PENDING, to Klima(timeout 3.5 s)  # OBD TestFailed Flag, Statusbotschaft für die elektrischen Kältemittelexpansionsventile
            signal EASV3_Err_RAMROMNADChange_TNCTOC_XIX_EASV3s_01_Status_XIX_Klima_LIN6: start 55, 1 bit, little-endian, data-type-policy=OVERRIDE, i-signal-type=PRIMITIVE, init-value=1, base-type=BT_EASV3_Err_RAMROMNADChange_TNCTOC, compu {0=Cx0_DTC_test_completed_this_operation_cylce (CM_EASV3_Err_RAMROMNADChange_TNCTOC_Cx0_DTC_test_completed_this_operation_cylce), 1=Cx1_DTC_test_not_completed_this_operation_cylce (CM_EASV3_Err_RAMROMNADChange_TNCTOC_Cx1_DTC_test_not_completed_this_operation_cylce)}, range raw 0..1, transfer-property=PENDING, to Klima(timeout 3.5 s)  # OBD TestFailed Flag, Statusbotschaft für die elektrischen Kältemittelexpansionsventile
            signal EASV3_Err_Notlaufpos_TF_XIX_EASV3s_01_Status_XIX_Klima_LIN6: start 56, 1 bit, little-endian, data-type-policy=OVERRIDE, i-signal-type=PRIMITIVE, base-type=BT_EASV3_Err_Notlaufpos_TF, compu {0=Cx0_passive (CM_EASV3_Err_Notlaufpos_TF_Cx0_passive), 1=Cx1_active (CM_EASV3_Err_Notlaufpos_TF_Cx1_active)}, range raw 0..1, transfer-property=PENDING, to Klima(timeout 3.5 s)  # OBD TestFailed Flag, Statusbotschaft für die elektrischen Kältemittelexpansionsventile
            signal EASV3_Err_Notlaufpos_TNCTOC_XIX_EASV3s_01_Status_XIX_Klima_LIN6: start 57, 1 bit, little-endian, data-type-policy=OVERRIDE, i-signal-type=PRIMITIVE, init-value=1, base-type=BT_EASV3_Err_Notlaufpos_TNCTOC, compu {0=Cx0_DTC_test_completed_this_operation_cylce (CM_EASV3_Err_Notlaufpos_TNCTOC_Cx0_DTC_test_completed_this_operation_cylce), 1=Cx1_DTC_test_not_completed_this_operation_cylce (CM_EASV3_Err_Notlaufpos_TNCTOC_Cx1_DTC_test_not_completed_this_operation_cylce)}, range raw 0..1, transfer-property=PENDING, to Klima(timeout 3.5 s)  # OBD TestFailed Flag, Statusbotschaft für die elektrischen Kältemittelexpansionsventile
        frame EASV4s_01_Status_XIX_Klima_LIN6: id 0x2D, to Klima, frame-length=8, lin-checksum=ENHANCED
          pdu EASV4s_01_Status_XIX_Klima_LIN6: length=8, unused-bit-pattern=0
            signal EASV4_Ist_Position_Aktuator_XIX_EASV4s_01_Status_XIX_Klima_LIN6: start 0, 16 bit, little-endian, data-type-policy=OVERRIDE, i-signal-type=PRIMITIVE, init-value=65534, base-type=BT_EASV4_Ist_Position_Aktuator, invalid-value=Invalid_EASV4_Ist_Position_Aktuator_XIX_EASV4s_01_Status_XIX_Klima_LIN6:65535, compu {phys=raw for raw 0..65533, 65534=Cxfffe_Init (CM_EASV4_Ist_Position_Aktuator_Cxfffe_Init), 65535=Cxffff_Fehler (CM_EASV4_Ist_Position_Aktuator_Cxffff_Fehler); unit Unit_None}, range phys 0..65533 Unit_None, raw 0..65535, unit=Unit_None, transfer-property=PENDING, to Klima(timeout 3.5 s)  # Statusbotschaft für die elektrischen Kältemittelabsperrventile
            signal EASV4_Geschwindigkeitsstatus_XIX_EASV4s_01_Status_XIX_Klima_LIN6: start 16, 4 bit, little-endian, data-type-policy=OVERRIDE, i-signal-type=PRIMITIVE, base-type=BT_EASV4_Geschwindigkeitsstatus, invalid-value=Invalid_EASV4_Geschwindigkeitsstatus_XIX_EASV4s_01_Status_XIX_Klima_LIN6:15, compu {0=Cx0_Motor_steht (CM_EASV4_Geschwindigkeitsstatus_Cx0_Motor_steht), 1=Cx1_Geschwindigkeitsstufe_1 (CM_EASV4_Geschwindigkeitsstatus_Cx1_Geschwindigkeitsstufe_1), 2=Cx2_Geschwindigkeitsstufe_2 (CM_EASV4_Geschwindigkeitsstatus_Cx2_Geschwindigkeitsstufe_2), 3=Cx3_Geschwindigkeitsstufe_3 (CM_EASV4_Geschwindigkeitsstatus_Cx3_Geschwindigkeitsstufe_3), 4=Cx4_Geschwindigkeitsstufe_4 (CM_EASV4_Geschwindigkeitsstatus_Cx4_Geschwindigkeitsstufe_4), 5=Cx5_Autospeed (CM_EASV4_Geschwindigkeitsstatus_Cx5_Autospeed), 15=Cxf_Fehler (CM_EASV4_Geschwindigkeitsstatus_Cxf_Fehler)}, range raw 0..15, transfer-property=PENDING, to Klima(timeout 3.5 s)  # Statusbotschaft für die elektrischen Kältemittelabsperrventile
            signal EASV4_Temp_Warning_XIX_EASV4s_01_Status_XIX_Klima_LIN6: start 20, 1 bit, little-endian, data-type-policy=OVERRIDE, i-signal-type=PRIMITIVE, base-type=BT_EASV4_Temp_Warning, compu {0=Cx0_keine_Warnschwelle (CM_EASV4_Temp_Warning_Cx0_keine_Warnschwelle), 1=Cx1_Warnschwelle_erreicht (CM_EASV4_Temp_Warning_Cx1_Warnschwelle_erreicht)}, range raw 0..1, transfer-property=PENDING, to Klima(timeout 3.5 s)  # Statusbotschaft für die elektrischen Kältemittelabsperrventile
            signal EASV4_Temp_XIX_EASV4s_01_Status_XIX_Klima_LIN6: start 24, 8 bit, little-endian, data-type-policy=OVERRIDE, i-signal-type=PRIMITIVE, init-value=254, base-type=BT_EASV4_Temp, invalid-value=Invalid_EASV4_Temp_XIX_EASV4s_01_Status_XIX_Klima_LIN6:255, compu {phys=raw-50 for raw 0..253, 254=Cxfe_Init (CM_EASV4_Temp_Cxfe_Init), 255=Cxff_Fehler (CM_EASV4_Temp_Cxff_Fehler); unit Unit_DegreCelsi}, range phys -50..203 Unit_DegreCelsi, raw 0..255, unit=Unit_DegreCelsi, transfer-property=PENDING, to Klima(timeout 3.5 s)  # Platinentemperatur, Statusbotschaft für die elektrischen Kältemittelabsperrventile
            signal EASV4_Spulenbestromung_XIX_EASV4s_01_Status_XIX_Klima_LIN6: start 32, 2 bit, little-endian, data-type-policy=OVERRIDE, i-signal-type=PRIMITIVE, base-type=BT_EASV4_Spulenbestromung, invalid-value=Invalid_EASV4_Spulenbestromung_XIX_EASV4s_01_Status_XIX_Klima_LIN6:3, compu {0=Cx0_Motorspulen_unbestromt (CM_EASV4_Spulenbestromung_Cx0_Motorspulen_unbestromt), 1=Cx1_Motorspulen_bestromt (CM_EASV4_Spulenbestromung_Cx1_Motorspulen_bestromt), 2=Cx2_reserviert (CM_EASV4_Spulenbestromung_Cx2_reserviert), 3=Cx3_Fehler (CM_EASV4_Spulenbestromung_Cx3_Fehler)}, range raw 0..3, transfer-property=PENDING, to Klima(timeout 3.5 s)  # Statusbotschaft für die elektrischen Kältemittelabsperrventile
            signal EASV4_ErrMem_State_XIX_EASV4s_01_Status_XIX_Klima_LIN6: start 38, 2 bit, little-endian, data-type-policy=OVERRIDE, i-signal-type=PRIMITIVE, init-value=2, base-type=BT_EASV4_ErrMem_State, compu {1=Cx1_ErrMem_Active (CM_EASV4_ErrMem_State_Cx1_ErrMem_Active), 2=Cx2_ErrMem_Init_Progress (CM_EASV4_ErrMem_State_Cx2_ErrMem_Init_Progress), 3=Cx3_ErrMem_Init_Done (CM_EASV4_ErrMem_State_Cx3_ErrMem_Init_Done)}, range raw 1..3, transfer-property=PENDING, to Klima(timeout 3.5 s)  # Error Memory State
            signal EASV4_ResponseError_XIX_EASV4s_01_Status_XIX_Klima_LIN6: start 40, 1 bit, little-endian, data-type-policy=OVERRIDE, i-signal-type=PRIMITIVE, init-value=0, base-type=BT_EASV4_ResponseError, invalid-value=Invalid_EASV4_ResponseError_XIX_EASV4s_01_Status_XIX_Klima_LIN6:1, compu {0=Cx0_normal (CM_EASV4_ResponseError_Cx0_normal), 1=Cx1_Fehler (CM_EASV4_ResponseError_Cx1_Fehler)}, range raw 0..1, transfer-property=PENDING, to Klima(timeout 3.5 s)  # siehe LIN2.0-Specification (Darf nicht über ein Fehlergueltigkeitsbit abgesichtert werden!)
            signal EASV4_ResponseError_TNCTOC_XIX_EASV4s_01_Status_XIX_Klima_LIN6: start 41, 1 bit, little-endian, data-type-policy=OVERRIDE, i-signal-type=PRIMITIVE, init-value=1, base-type=BT_EASV4_ResponseError_TNCTOC, compu {0=Cx0_DTC_test_completed_this_operation_cylce (CM_EASV4_ResponseError_TNCTOC_Cx0_DTC_test_completed_this_operation_cylce), 1=Cx1_DTC_test_not_completed_this_operation_cylce (CM_EASV4_ResponseError_TNCTOC_Cx1_DTC_test_not_completed_this_operation_cylce)}, range raw 0..1, transfer-property=PENDING, to Klima(timeout 3.5 s)  # OBD TestFailed Flag, Statusbotschaft für die elektrischen Kältemittelexpansionsventile
            signal EASV4_Err_EDefekt_MoKomp_TF_XIX_EASV4s_01_Status_XIX_Klima_LIN6: start 42, 1 bit, little-endian, data-type-policy=OVERRIDE, i-signal-type=PRIMITIVE, base-type=BT_EASV4_Err_EDefekt_MoKomp_TF, compu {0=Cx0_passive (CM_EASV4_Err_EDefekt_MoKomp_TF_Cx0_passive), 1=Cx1_active (CM_EASV4_Err_EDefekt_MoKomp_TF_Cx1_active)}, range raw 0..1, transfer-property=PENDING, to Klima(timeout 3.5 s)  # OBD TestFailed Flag, Statusbotschaft für die elektrischen Kältemittelexpansionsventile
            signal EASV4_Err_EDefekt_MoKomp_TNCTOC_XIX_EASV4s_01_Status_XIX_Klima_LIN6: start 43, 1 bit, little-endian, data-type-policy=OVERRIDE, i-signal-type=PRIMITIVE, init-value=1, base-type=BT_EASV4_Err_EDefekt_MoKomp_TNCTOC, compu {0=Cx0_DTC_test_completed_this_operation_cylce (CM_EASV4_Err_EDefekt_MoKomp_TNCTOC_Cx0_DTC_test_completed_this_operation_cylce), 1=Cx1_DTC_test_not_completed_this_operation_cylce (CM_EASV4_Err_EDefekt_MoKomp_TNCTOC_Cx1_DTC_test_not_completed_this_operation_cylce)}, range raw 0..1, transfer-property=PENDING, to Klima(timeout 3.5 s)  # OBD TestFailed Flag, Statusbotschaft für die elektrischen Kältemittelexpansionsventile
            signal EASV4_Err_EDefekt_TSens_TF_XIX_EASV4s_01_Status_XIX_Klima_LIN6: start 44, 1 bit, little-endian, data-type-policy=OVERRIDE, i-signal-type=PRIMITIVE, base-type=BT_EASV4_Err_EDefekt_TSens_TF, compu {0=Cx0_passive (CM_EASV4_Err_EDefekt_TSens_TF_Cx0_passive), 1=Cx1_active (CM_EASV4_Err_EDefekt_TSens_TF_Cx1_active)}, range raw 0..1, transfer-property=PENDING, to Klima(timeout 3.5 s)  # OBD TestFailed Flag, Statusbotschaft für die elektrischen Kältemittelexpansionsventile
            signal EASV4_Err_EDefekt_TSens_TNCTOC_XIX_EASV4s_01_Status_XIX_Klima_LIN6: start 45, 1 bit, little-endian, data-type-policy=OVERRIDE, i-signal-type=PRIMITIVE, init-value=1, base-type=BT_EASV4_Err_EDefekt_TSens_TNCTOC, compu {0=Cx0_DTC_test_completed_this_operation_cylce (CM_EASV4_Err_EDefekt_TSens_TNCTOC_Cx0_DTC_test_completed_this_operation_cylce), 1=Cx1_DTC_test_not_completed_this_operation_cylce (CM_EASV4_Err_EDefekt_TSens_TNCTOC_Cx1_DTC_test_not_completed_this_operation_cylce)}, range raw 0..1, transfer-property=PENDING, to Klima(timeout 3.5 s)  # OBD TestFailed Flag, Statusbotschaft für die elektrischen Kältemittelexpansionsventile
            signal EASV4_Err_Uebertemperatur_TF_XIX_EASV4s_01_Status_XIX_Klima_LIN6: start 46, 1 bit, little-endian, data-type-policy=OVERRIDE, i-signal-type=PRIMITIVE, base-type=BT_EASV4_Err_Uebertemperatur_TF, compu {0=Cx0_passive (CM_EASV4_Err_Uebertemperatur_TF_Cx0_passive), 1=Cx1_active (CM_EASV4_Err_Uebertemperatur_TF_Cx1_active)}, range raw 0..1, transfer-property=PENDING, to Klima(timeout 3.5 s)  # OBD TestFailed Flag, Statusbotschaft für die elektrischen Kältemittelabsperrventile
            signal EASV4_Err_Uebertemperatur_TNCTOC_XIX_EASV4s_01_Status_XIX_Klima_LIN6: start 47, 1 bit, little-endian, data-type-policy=OVERRIDE, i-signal-type=PRIMITIVE, init-value=1, base-type=BT_EASV4_Err_Uebertemperatur_TNCTOC, compu {0=Cx0_DTC_test_completed_this_operation_cylce (CM_EASV4_Err_Uebertemperatur_TNCTOC_Cx0_DTC_test_completed_this_operation_cylce), 1=Cx1_DTC_test_not_completed_this_operation_cylce (CM_EASV4_Err_Uebertemperatur_TNCTOC_Cx1_DTC_test_not_completed_this_operation_cylce)}, range raw 0..1, transfer-property=PENDING, to Klima(timeout 3.5 s)  # OBD TestFailed Flag, Statusbotschaft für die elektrischen Kältemittelexpansionsventile
            signal EASV4_Err_Ueberspannung_TF_XIX_EASV4s_01_Status_XIX_Klima_LIN6: start 48, 1 bit, little-endian, data-type-policy=OVERRIDE, i-signal-type=PRIMITIVE, base-type=BT_EASV4_Err_Ueberspannung_TF, compu {0=Cx0_passive (CM_EASV4_Err_Ueberspannung_TF_Cx0_passive), 1=Cx1_active (CM_EASV4_Err_Ueberspannung_TF_Cx1_active)}, range raw 0..1, transfer-property=PENDING, to Klima(timeout 3.5 s)  # OBD TestFailed Flag, Statusbotschaft für die elektrischen Kältemittelexpansionsventile
            signal EASV4_Err_Ueberspannung_TNCTOC_XIX_EASV4s_01_Status_XIX_Klima_LIN6: start 49, 1 bit, little-endian, data-type-policy=OVERRIDE, i-signal-type=PRIMITIVE, init-value=1, base-type=BT_EASV4_Err_Ueberspannung_TNCTOC, compu {0=Cx0_DTC_test_completed_this_operation_cylce (CM_EASV4_Err_Ueberspannung_TNCTOC_Cx0_DTC_test_completed_this_operation_cylce), 1=Cx1_DTC_test_not_completed_this_operation_cylce (CM_EASV4_Err_Ueberspannung_TNCTOC_Cx1_DTC_test_not_completed_this_operation_cylce)}, range raw 0..1, transfer-property=PENDING, to Klima(timeout 3.5 s)  # OBD TestFailed Flag, Statusbotschaft für die elektrischen Kältemittelexpansionsventile
            signal EASV4_Err_Unterspannung_TF_XIX_EASV4s_01_Status_XIX_Klima_LIN6: start 50, 1 bit, little-endian, data-type-policy=OVERRIDE, i-signal-type=PRIMITIVE, base-type=BT_EASV4_Err_Unterspannung_TF, compu {0=Cx0_passive (CM_EASV4_Err_Unterspannung_TF_Cx0_passive), 1=Cx1_active (CM_EASV4_Err_Unterspannung_TF_Cx1_active)}, range raw 0..1, transfer-property=PENDING, to Klima(timeout 3.5 s)  # OBD TestFailed Flag, Statusbotschaft für die elektrischen Kältemittelexpansionsventile
            signal EASV4_Err_Unterspannung_TNCTOC_XIX_EASV4s_01_Status_XIX_Klima_LIN6: start 51, 1 bit, little-endian, data-type-policy=OVERRIDE, i-signal-type=PRIMITIVE, init-value=1, base-type=BT_EASV4_Err_Unterspannung_TNCTOC, compu {0=Cx0_DTC_test_completed_this_operation_cylce (CM_EASV4_Err_Unterspannung_TNCTOC_Cx0_DTC_test_completed_this_operation_cylce), 1=Cx1_DTC_test_not_completed_this_operation_cylce (CM_EASV4_Err_Unterspannung_TNCTOC_Cx1_DTC_test_not_completed_this_operation_cylce)}, range raw 0..1, transfer-property=PENDING, to Klima(timeout 3.5 s)  # OBD TestFailed Flag, Statusbotschaft für die elektrischen Kältemittelexpansionsventile
            signal EASV4_Err_Blockierung_TF_XIX_EASV4s_01_Status_XIX_Klima_LIN6: start 52, 1 bit, little-endian, data-type-policy=OVERRIDE, i-signal-type=PRIMITIVE, base-type=BT_EASV4_Err_Blockierung_TF, compu {0=Cx0_passive (CM_EASV4_Err_Blockierung_TF_Cx0_passive), 1=Cx1_active (CM_EASV4_Err_Blockierung_TF_Cx1_active)}, range raw 0..1, transfer-property=PENDING, to Klima(timeout 3.5 s)  # OBD TestFailed Flag, Statusbotschaft für die elektrischen Kältemittelexpansionsventile
            signal EASV4_Err_Blockierung_TNCTOC_XIX_EASV4s_01_Status_XIX_Klima_LIN6: start 53, 1 bit, little-endian, data-type-policy=OVERRIDE, i-signal-type=PRIMITIVE, init-value=1, base-type=BT_EASV4_Err_Blockierung_TNCTOC, compu {0=Cx0_DTC_test_completed_this_operation_cylce (CM_EASV4_Err_Blockierung_TNCTOC_Cx0_DTC_test_completed_this_operation_cylce), 1=Cx1_DTC_test_not_completed_this_operation_cylce (CM_EASV4_Err_Blockierung_TNCTOC_Cx1_DTC_test_not_completed_this_operation_cylce)}, range raw 0..1, transfer-property=PENDING, to Klima(timeout 3.5 s)  # OBD TestFailed Flag, Statusbotschaft für die elektrischen Kältemittelexpansionsventile
            signal EASV4_Err_RAMROMNADChange_TF_XIX_EASV4s_01_Status_XIX_Klima_LIN6: start 54, 1 bit, little-endian, data-type-policy=OVERRIDE, i-signal-type=PRIMITIVE, base-type=BT_EASV4_Err_RAMROMNADChange_TF, compu {0=Cx0_passive (CM_EASV4_Err_RAMROMNADChange_TF_Cx0_passive), 1=Cx1_active (CM_EASV4_Err_RAMROMNADChange_TF_Cx1_active)}, range raw 0..1, transfer-property=PENDING, to Klima(timeout 3.5 s)  # OBD TestFailed Flag, Statusbotschaft für die elektrischen Kältemittelexpansionsventile
            signal EASV4_Err_RAMROMNADChange_TNCTOC_XIX_EASV4s_01_Status_XIX_Klima_LIN6: start 55, 1 bit, little-endian, data-type-policy=OVERRIDE, i-signal-type=PRIMITIVE, init-value=1, base-type=BT_EASV4_Err_RAMROMNADChange_TNCTOC, compu {0=Cx0_DTC_test_completed_this_operation_cylce (CM_EASV4_Err_RAMROMNADChange_TNCTOC_Cx0_DTC_test_completed_this_operation_cylce), 1=Cx1_DTC_test_not_completed_this_operation_cylce (CM_EASV4_Err_RAMROMNADChange_TNCTOC_Cx1_DTC_test_not_completed_this_operation_cylce)}, range raw 0..1, transfer-property=PENDING, to Klima(timeout 3.5 s)  # OBD TestFailed Flag, Statusbotschaft für die elektrischen Kältemittelexpansionsventile
            signal EASV4_Err_Notlaufpos_TF_XIX_EASV4s_01_Status_XIX_Klima_LIN6: start 56, 1 bit, little-endian, data-type-policy=OVERRIDE, i-signal-type=PRIMITIVE, base-type=BT_EASV4_Err_Notlaufpos_TF, compu {0=Cx0_passive (CM_EASV4_Err_Notlaufpos_TF_Cx0_passive), 1=Cx1_active (CM_EASV4_Err_Notlaufpos_TF_Cx1_active)}, range raw 0..1, transfer-property=PENDING, to Klima(timeout 3.5 s)  # OBD TestFailed Flag, Statusbotschaft für die elektrischen Kältemittelexpansionsventile
            signal EASV4_Err_Notlaufpos_TNCTOC_XIX_EASV4s_01_Status_XIX_Klima_LIN6: start 57, 1 bit, little-endian, data-type-policy=OVERRIDE, i-signal-type=PRIMITIVE, init-value=1, base-type=BT_EASV4_Err_Notlaufpos_TNCTOC, compu {0=Cx0_DTC_test_completed_this_operation_cylce (CM_EASV4_Err_Notlaufpos_TNCTOC_Cx0_DTC_test_completed_this_operation_cylce), 1=Cx1_DTC_test_not_completed_this_operation_cylce (CM_EASV4_Err_Notlaufpos_TNCTOC_Cx1_DTC_test_not_completed_this_operation_cylce)}, range raw 0..1, transfer-property=PENDING, to Klima(timeout 3.5 s)  # OBD TestFailed Flag, Statusbotschaft für die elektrischen Kältemittelexpansionsventile
        frame EASV5s_01_Status_XIX_Klima_LIN6: id 0x2E, to Klima, frame-length=8, lin-checksum=ENHANCED
          pdu EASV5s_01_Status_XIX_Klima_LIN6: length=8, unused-bit-pattern=0
            signal EASV5_Ist_Position_Aktuator_XIX_EASV5s_01_Status_XIX_Klima_LIN6: start 0, 16 bit, little-endian, data-type-policy=OVERRIDE, i-signal-type=PRIMITIVE, init-value=65534, base-type=BT_EASV5_Ist_Position_Aktuator, invalid-value=Invalid_EASV5_Ist_Position_Aktuator_XIX_EASV5s_01_Status_XIX_Klima_LIN6:65535, compu {phys=raw for raw 0..65533, 65534=Cxfffe_Init (CM_EASV5_Ist_Position_Aktuator_Cxfffe_Init), 65535=Cxffff_Fehler (CM_EASV5_Ist_Position_Aktuator_Cxffff_Fehler); unit Unit_None}, range phys 0..65533 Unit_None, raw 0..65535, unit=Unit_None, transfer-property=PENDING, to Klima(timeout 3.5 s)  # Statusbotschaft für die elektrischen Kältemittelabsperrventile
            signal EASV5_Geschwindigkeitsstatus_XIX_EASV5s_01_Status_XIX_Klima_LIN6: start 16, 4 bit, little-endian, data-type-policy=OVERRIDE, i-signal-type=PRIMITIVE, base-type=BT_EASV5_Geschwindigkeitsstatus, invalid-value=Invalid_EASV5_Geschwindigkeitsstatus_XIX_EASV5s_01_Status_XIX_Klima_LIN6:15, compu {0=Cx0_Motor_steht (CM_EASV5_Geschwindigkeitsstatus_Cx0_Motor_steht), 1=Cx1_Geschwindigkeitsstufe_1 (CM_EASV5_Geschwindigkeitsstatus_Cx1_Geschwindigkeitsstufe_1), 2=Cx2_Geschwindigkeitsstufe_2 (CM_EASV5_Geschwindigkeitsstatus_Cx2_Geschwindigkeitsstufe_2), 3=Cx3_Geschwindigkeitsstufe_3 (CM_EASV5_Geschwindigkeitsstatus_Cx3_Geschwindigkeitsstufe_3), 4=Cx4_Geschwindigkeitsstufe_4 (CM_EASV5_Geschwindigkeitsstatus_Cx4_Geschwindigkeitsstufe_4), 5=Cx5_Autospeed (CM_EASV5_Geschwindigkeitsstatus_Cx5_Autospeed), 15=Cxf_Fehler (CM_EASV5_Geschwindigkeitsstatus_Cxf_Fehler)}, range raw 0..15, transfer-property=PENDING, to Klima(timeout 3.5 s)  # Statusbotschaft für die elektrischen Kältemittelabsperrventile
            signal EASV5_Temp_Warning_XIX_EASV5s_01_Status_XIX_Klima_LIN6: start 20, 1 bit, little-endian, data-type-policy=OVERRIDE, i-signal-type=PRIMITIVE, base-type=BT_EASV5_Temp_Warning, compu {0=Cx0_keine_Warnschwelle (CM_EASV5_Temp_Warning_Cx0_keine_Warnschwelle), 1=Cx1_Warnschwelle_erreicht (CM_EASV5_Temp_Warning_Cx1_Warnschwelle_erreicht)}, range raw 0..1, transfer-property=PENDING, to Klima(timeout 3.5 s)  # Statusbotschaft für die elektrischen Kältemittelabsperrventile
            signal EASV5_temp_XIX_EASV5s_01_Status_XIX_Klima_LIN6: start 24, 8 bit, little-endian, data-type-policy=OVERRIDE, i-signal-type=PRIMITIVE, init-value=254, base-type=BT_EASV5_temp, invalid-value=Invalid_EASV5_temp_XIX_EASV5s_01_Status_XIX_Klima_LIN6:255, compu {phys=raw-50 for raw 0..253, 254=Cxfe_Init (CM_EASV5_temp_Cxfe_Init), 255=Cxff_Fehler (CM_EASV5_temp_Cxff_Fehler); unit Unit_DegreCelsi}, range phys -50..203 Unit_DegreCelsi, raw 0..255, unit=Unit_DegreCelsi, transfer-property=PENDING, to Klima(timeout 3.5 s)  # Platinentemperatur, Statusbotschaft für die elektrischen Kältemittelabsperrventile
            signal EASV5_Spulenbestromung_XIX_EASV5s_01_Status_XIX_Klima_LIN6: start 32, 2 bit, little-endian, data-type-policy=OVERRIDE, i-signal-type=PRIMITIVE, base-type=BT_EASV5_Spulenbestromung, invalid-value=Invalid_EASV5_Spulenbestromung_XIX_EASV5s_01_Status_XIX_Klima_LIN6:3, compu {0=Cx0_Motorspulen_unbestromt (CM_EASV5_Spulenbestromung_Cx0_Motorspulen_unbestromt), 1=Cx1_Motorspulen_bestromt (CM_EASV5_Spulenbestromung_Cx1_Motorspulen_bestromt), 2=Cx2_reserviert (CM_EASV5_Spulenbestromung_Cx2_reserviert), 3=Cx3_Fehler (CM_EASV5_Spulenbestromung_Cx3_Fehler)}, range raw 0..3, transfer-property=PENDING, to Klima(timeout 3.5 s)  # Statusbotschaft für die elektrischen Kältemittelabsperrventile
            signal EASV5_ErrMem_State_XIX_EASV5s_01_Status_XIX_Klima_LIN6: start 38, 2 bit, little-endian, data-type-policy=OVERRIDE, i-signal-type=PRIMITIVE, init-value=2, base-type=BT_EASV5_ErrMem_State, compu {1=Cx1_ErrMem_Active (CM_EASV5_ErrMem_State_Cx1_ErrMem_Active), 2=Cx2_ErrMem_Init_Progress (CM_EASV5_ErrMem_State_Cx2_ErrMem_Init_Progress), 3=Cx3_ErrMem_Init_Done (CM_EASV5_ErrMem_State_Cx3_ErrMem_Init_Done)}, range raw 1..3, transfer-property=PENDING, to Klima(timeout 3.5 s)  # Error Memory State
            signal EASV5_ResponseError_XIX_EASV5s_01_Status_XIX_Klima_LIN6: start 40, 1 bit, little-endian, data-type-policy=OVERRIDE, i-signal-type=PRIMITIVE, init-value=0, base-type=BT_EASV5_ResponseError, invalid-value=Invalid_EASV5_ResponseError_XIX_EASV5s_01_Status_XIX_Klima_LIN6:1, compu {0=Cx0_normal (CM_EASV5_ResponseError_Cx0_normal), 1=Cx1_Fehler (CM_EASV5_ResponseError_Cx1_Fehler)}, range raw 0..1, transfer-property=PENDING, to Klima(timeout 3.5 s)  # siehe LIN2.0-Specification (Darf nicht über ein Fehlergueltigkeitsbit abgesichtert werden!)
            signal EASV5_ResponseError_TNCTOC_XIX_EASV5s_01_Status_XIX_Klima_LIN6: start 41, 1 bit, little-endian, data-type-policy=OVERRIDE, i-signal-type=PRIMITIVE, init-value=1, base-type=BT_EASV5_ResponseError_TNCTOC, compu {0=Cx0_DTC_test_completed_this_operation_cylce (CM_EASV5_ResponseError_TNCTOC_Cx0_DTC_test_completed_this_operation_cylce), 1=Cx1_DTC_test_not_completed_this_operation_cylce (CM_EASV5_ResponseError_TNCTOC_Cx1_DTC_test_not_completed_this_operation_cylce)}, range raw 0..1, transfer-property=PENDING, to Klima(timeout 3.5 s)  # OBD TestFailed Flag, Statusbotschaft für die elektrischen Kältemittelexpansionsventile
            signal EASV5_Err_EDefekt_MoKomp_TF_XIX_EASV5s_01_Status_XIX_Klima_LIN6: start 42, 1 bit, little-endian, data-type-policy=OVERRIDE, i-signal-type=PRIMITIVE, base-type=BT_EASV5_Err_EDefekt_MoKomp_TF, compu {0=Cx0_passive (CM_EASV5_Err_EDefekt_MoKomp_TF_Cx0_passive), 1=Cx1_active (CM_EASV5_Err_EDefekt_MoKomp_TF_Cx1_active)}, range raw 0..1, transfer-property=PENDING, to Klima(timeout 3.5 s)  # OBD TestFailed Flag, Statusbotschaft für die elektrischen Kältemittelexpansionsventile
            signal EASV5_Err_EDefekt_MoKomp_TNCTOC_XIX_EASV5s_01_Status_XIX_Klima_LIN6: start 43, 1 bit, little-endian, data-type-policy=OVERRIDE, i-signal-type=PRIMITIVE, init-value=1, base-type=BT_EASV5_Err_EDefekt_MoKomp_TNCTOC, compu {0=Cx0_DTC_test_completed_this_operation_cylce (CM_EASV5_Err_EDefekt_MoKomp_TNCTOC_Cx0_DTC_test_completed_this_operation_cylce), 1=Cx1_DTC_test_not_completed_this_operation_cylce (CM_EASV5_Err_EDefekt_MoKomp_TNCTOC_Cx1_DTC_test_not_completed_this_operation_cylce)}, range raw 0..1, transfer-property=PENDING, to Klima(timeout 3.5 s)  # OBD TestFailed Flag, Statusbotschaft für die elektrischen Kältemittelexpansionsventile
            signal EASV5_Err_EDefekt_TSens_TF_XIX_EASV5s_01_Status_XIX_Klima_LIN6: start 44, 1 bit, little-endian, data-type-policy=OVERRIDE, i-signal-type=PRIMITIVE, base-type=BT_EASV5_Err_EDefekt_TSens_TF, compu {0=Cx0_passive (CM_EASV5_Err_EDefekt_TSens_TF_Cx0_passive), 1=Cx1_active (CM_EASV5_Err_EDefekt_TSens_TF_Cx1_active)}, range raw 0..1, transfer-property=PENDING, to Klima(timeout 3.5 s)  # OBD TestFailed Flag, Statusbotschaft für die elektrischen Kältemittelexpansionsventile
            signal EASV5_Err_EDefekt_TSens_TNCTOC_XIX_EASV5s_01_Status_XIX_Klima_LIN6: start 45, 1 bit, little-endian, data-type-policy=OVERRIDE, i-signal-type=PRIMITIVE, init-value=1, base-type=BT_EASV5_Err_EDefekt_TSens_TNCTOC, compu {0=Cx0_DTC_test_completed_this_operation_cylce (CM_EASV5_Err_EDefekt_TSens_TNCTOC_Cx0_DTC_test_completed_this_operation_cylce), 1=Cx1_DTC_test_not_completed_this_operation_cylce (CM_EASV5_Err_EDefekt_TSens_TNCTOC_Cx1_DTC_test_not_completed_this_operation_cylce)}, range raw 0..1, transfer-property=PENDING, to Klima(timeout 3.5 s)  # OBD TestFailed Flag, Statusbotschaft für die elektrischen Kältemittelexpansionsventile
            signal EASV5_Err_Uebertemperatur_TF_XIX_EASV5s_01_Status_XIX_Klima_LIN6: start 46, 1 bit, little-endian, data-type-policy=OVERRIDE, i-signal-type=PRIMITIVE, base-type=BT_EASV5_Err_Uebertemperatur_TF, compu {0=Cx0_passive (CM_EASV5_Err_Uebertemperatur_TF_Cx0_passive), 1=Cx1_active (CM_EASV5_Err_Uebertemperatur_TF_Cx1_active)}, range raw 0..1, transfer-property=PENDING, to Klima(timeout 3.5 s)  # OBD TestFailed Flag, Statusbotschaft für die elektrischen Kältemittelabsperrventile
            signal EASV5_Err_Uebertemperatur_TNCTOC_XIX_EASV5s_01_Status_XIX_Klima_LIN6: start 47, 1 bit, little-endian, data-type-policy=OVERRIDE, i-signal-type=PRIMITIVE, init-value=1, base-type=BT_EASV5_Err_Uebertemperatur_TNCTOC, compu {0=Cx0_DTC_test_completed_this_operation_cylce (CM_EASV5_Err_Uebertemperatur_TNCTOC_Cx0_DTC_test_completed_this_operation_cylce), 1=Cx1_DTC_test_not_completed_this_operation_cylce (CM_EASV5_Err_Uebertemperatur_TNCTOC_Cx1_DTC_test_not_completed_this_operation_cylce)}, range raw 0..1, transfer-property=PENDING, to Klima(timeout 3.5 s)  # OBD TestFailed Flag, Statusbotschaft für die elektrischen Kältemittelexpansionsventile
            signal EASV5_Err_Ueberspannung_TF_XIX_EASV5s_01_Status_XIX_Klima_LIN6: start 48, 1 bit, little-endian, data-type-policy=OVERRIDE, i-signal-type=PRIMITIVE, base-type=BT_EASV5_Err_Ueberspannung_TF, compu {0=Cx0_passive (CM_EASV5_Err_Ueberspannung_TF_Cx0_passive), 1=Cx1_active (CM_EASV5_Err_Ueberspannung_TF_Cx1_active)}, range raw 0..1, transfer-property=PENDING, to Klima(timeout 3.5 s)  # OBD TestFailed Flag, Statusbotschaft für die elektrischen Kältemittelexpansionsventile
            signal EASV5_Err_Ueberspannung_TNCTOC_XIX_EASV5s_01_Status_XIX_Klima_LIN6: start 49, 1 bit, little-endian, data-type-policy=OVERRIDE, i-signal-type=PRIMITIVE, init-value=1, base-type=BT_EASV5_Err_Ueberspannung_TNCTOC, compu {0=Cx0_DTC_test_completed_this_operation_cylce (CM_EASV5_Err_Ueberspannung_TNCTOC_Cx0_DTC_test_completed_this_operation_cylce), 1=Cx1_DTC_test_not_completed_this_operation_cylce (CM_EASV5_Err_Ueberspannung_TNCTOC_Cx1_DTC_test_not_completed_this_operation_cylce)}, range raw 0..1, transfer-property=PENDING, to Klima(timeout 3.5 s)  # OBD TestFailed Flag, Statusbotschaft für die elektrischen Kältemittelexpansionsventile
            signal EASV5_Err_Unterspannung_TF_XIX_EASV5s_01_Status_XIX_Klima_LIN6: start 50, 1 bit, little-endian, data-type-policy=OVERRIDE, i-signal-type=PRIMITIVE, base-type=BT_EASV5_Err_Unterspannung_TF, compu {0=Cx0_passive (CM_EASV5_Err_Unterspannung_TF_Cx0_passive), 1=Cx1_active (CM_EASV5_Err_Unterspannung_TF_Cx1_active)}, range raw 0..1, transfer-property=PENDING, to Klima(timeout 3.5 s)  # OBD TestFailed Flag, Statusbotschaft für die elektrischen Kältemittelexpansionsventile
            signal EASV5_Err_Unterspannung_TNCTOC_XIX_EASV5s_01_Status_XIX_Klima_LIN6: start 51, 1 bit, little-endian, data-type-policy=OVERRIDE, i-signal-type=PRIMITIVE, init-value=1, base-type=BT_EASV5_Err_Unterspannung_TNCTOC, compu {0=Cx0_DTC_test_completed_this_operation_cylce (CM_EASV5_Err_Unterspannung_TNCTOC_Cx0_DTC_test_completed_this_operation_cylce), 1=Cx1_DTC_test_not_completed_this_operation_cylce (CM_EASV5_Err_Unterspannung_TNCTOC_Cx1_DTC_test_not_completed_this_operation_cylce)}, range raw 0..1, transfer-property=PENDING, to Klima(timeout 3.5 s)  # OBD TestFailed Flag, Statusbotschaft für die elektrischen Kältemittelexpansionsventile
            signal EASV5_Err_Blockierung_TF_XIX_EASV5s_01_Status_XIX_Klima_LIN6: start 52, 1 bit, little-endian, data-type-policy=OVERRIDE, i-signal-type=PRIMITIVE, base-type=BT_EASV5_Err_Blockierung_TF, compu {0=Cx0_passive (CM_EASV5_Err_Blockierung_TF_Cx0_passive), 1=Cx1_active (CM_EASV5_Err_Blockierung_TF_Cx1_active)}, range raw 0..1, transfer-property=PENDING, to Klima(timeout 3.5 s)  # OBD TestFailed Flag, Statusbotschaft für die elektrischen Kältemittelexpansionsventile
            signal EASV5_Err_Blockierung_TNCTOC_XIX_EASV5s_01_Status_XIX_Klima_LIN6: start 53, 1 bit, little-endian, data-type-policy=OVERRIDE, i-signal-type=PRIMITIVE, init-value=1, base-type=BT_EASV5_Err_Blockierung_TNCTOC, compu {0=Cx0_DTC_test_completed_this_operation_cylce (CM_EASV5_Err_Blockierung_TNCTOC_Cx0_DTC_test_completed_this_operation_cylce), 1=Cx1_DTC_test_not_completed_this_operation_cylce (CM_EASV5_Err_Blockierung_TNCTOC_Cx1_DTC_test_not_completed_this_operation_cylce)}, range raw 0..1, transfer-property=PENDING, to Klima(timeout 3.5 s)  # OBD TestFailed Flag, Statusbotschaft für die elektrischen Kältemittelexpansionsventile
            signal EASV5_Err_RAMROMNADChange_TF_XIX_EASV5s_01_Status_XIX_Klima_LIN6: start 54, 1 bit, little-endian, data-type-policy=OVERRIDE, i-signal-type=PRIMITIVE, base-type=BT_EASV5_Err_RAMROMNADChange_TF, compu {0=Cx0_passive (CM_EASV5_Err_RAMROMNADChange_TF_Cx0_passive), 1=Cx1_active (CM_EASV5_Err_RAMROMNADChange_TF_Cx1_active)}, range raw 0..1, transfer-property=PENDING, to Klima(timeout 3.5 s)  # OBD TestFailed Flag, Statusbotschaft für die elektrischen Kältemittelexpansionsventile
            signal EASV5_Err_RAMROMNADChange_TNCTOC_XIX_EASV5s_01_Status_XIX_Klima_LIN6: start 55, 1 bit, little-endian, data-type-policy=OVERRIDE, i-signal-type=PRIMITIVE, init-value=1, base-type=BT_EASV5_Err_RAMROMNADChange_TNCTOC, compu {0=Cx0_DTC_test_completed_this_operation_cylce (CM_EASV5_Err_RAMROMNADChange_TNCTOC_Cx0_DTC_test_completed_this_operation_cylce), 1=Cx1_DTC_test_not_completed_this_operation_cylce (CM_EASV5_Err_RAMROMNADChange_TNCTOC_Cx1_DTC_test_not_completed_this_operation_cylce)}, range raw 0..1, transfer-property=PENDING, to Klima(timeout 3.5 s)  # OBD TestFailed Flag, Statusbotschaft für die elektrischen Kältemittelexpansionsventile
            signal EASV5_Err_Notlaufpos_TF_XIX_EASV5s_01_Status_XIX_Klima_LIN6: start 56, 1 bit, little-endian, data-type-policy=OVERRIDE, i-signal-type=PRIMITIVE, base-type=BT_EASV5_Err_Notlaufpos_TF, compu {0=Cx0_passive (CM_EASV5_Err_Notlaufpos_TF_Cx0_passive), 1=Cx1_active (CM_EASV5_Err_Notlaufpos_TF_Cx1_active)}, range raw 0..1, transfer-property=PENDING, to Klima(timeout 3.5 s)  # OBD TestFailed Flag, Statusbotschaft für die elektrischen Kältemittelexpansionsventile
            signal EASV5_Err_Notlaufpos_TNCTOC_XIX_EASV5s_01_Status_XIX_Klima_LIN6: start 57, 1 bit, little-endian, data-type-policy=OVERRIDE, i-signal-type=PRIMITIVE, init-value=1, base-type=BT_EASV5_Err_Notlaufpos_TNCTOC, compu {0=Cx0_DTC_test_completed_this_operation_cylce (CM_EASV5_Err_Notlaufpos_TNCTOC_Cx0_DTC_test_completed_this_operation_cylce), 1=Cx1_DTC_test_not_completed_this_operation_cylce (CM_EASV5_Err_Notlaufpos_TNCTOC_Cx1_DTC_test_not_completed_this_operation_cylce)}, range raw 0..1, transfer-property=PENDING, to Klima(timeout 3.5 s)  # OBD TestFailed Flag, Statusbotschaft für die elektrischen Kältemittelexpansionsventile
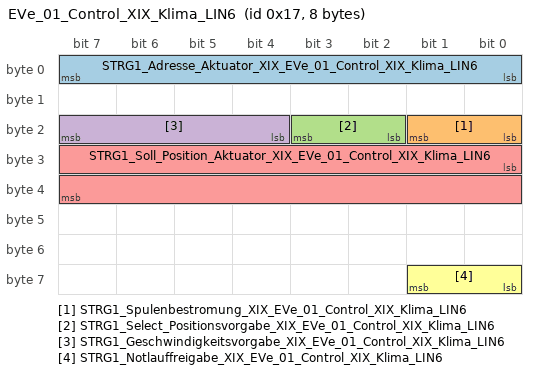
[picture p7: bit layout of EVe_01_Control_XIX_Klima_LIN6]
        frame EVe_01_Control_XIX_Klima_LIN6: id 0x17, from Klima, frame-length=8, lin-checksum=ENHANCED
          pdu EVe_01_Control_XIX_Klima_LIN6: length=8, unused-bit-pattern=0
            signal STRG1_Adresse_Aktuator_XIX_EVe_01_Control_XIX_Klima_LIN6: start 0, 8 bit, little-endian, data-type-policy=OVERRIDE, i-signal-type=PRIMITIVE, base-type=BT_STRG1_Adresse_Aktuator, invalid-value=Invalid_STRG1_Adresse_Aktuator_XIX_EVe_01_Control_XIX_Klima_LIN6:255, compu {phys=raw for raw 0..254, 127=Cx7f_Broadcast (CM_STRG1_Adresse_Aktuator_Cx7f_Broadcast), 255=Cxff_Fehler (CM_STRG1_Adresse_Aktuator_Cxff_Fehler); unit Unit_None}, range phys 0..254 Unit_None, raw 0..255, unit=Unit_None, transfer-property=PENDING  # Zielempfängerauswahl, Steuerungsbotschaft für Aktuatoren
            signal STRG1_Spulenbestromung_XIX_EVe_01_Control_XIX_Klima_LIN6: start 16, 2 bit, little-endian, data-type-policy=OVERRIDE, i-signal-type=PRIMITIVE, base-type=BT_STRG1_Spulenbestromung, invalid-value=Invalid_STRG1_Spulenbestromung_XIX_EVe_01_Control_XIX_Klima_LIN6:3, compu {0=Cx0_Motorspulen_unbestromt (CM_STRG1_Spulenbestromung_Cx0_Motorspulen_unbestromt), 1=Cx1_Motorspulen_bestromt (CM_STRG1_Spulenbestromung_Cx1_Motorspulen_bestromt), 2=Cx2_reserviert (CM_STRG1_Spulenbestromung_Cx2_reserviert), 3=Cx3_Fehler (CM_STRG1_Spulenbestromung_Cx3_Fehler)}, range raw 0..3, transfer-property=PENDING  # Spulenbestromungszustandsvorgabe, Steuerungsbotschaft für Aktuatoren
            signal STRG1_Select_Positionsvorgabe_XIX_EVe_01_Control_XIX_Klima_LIN6: start 18, 2 bit, little-endian, data-type-policy=OVERRIDE, i-signal-type=PRIMITIVE, init-value=2, base-type=BT_STRG1_Select_Positionsvorgabe, invalid-value=Invalid_STRG1_Select_Positionsvorgabe_XIX_EVe_01_Control_XIX_Klima_LIN6:3, compu {0=Cx0_Soll_Position_gueltig (CM_STRG1_Select_Positionsvorgabe_Cx0_Soll_Position_gueltig), 1=Cx1_Start_Position_gueltig (CM_STRG1_Select_Positionsvorgabe_Cx1_Start_Position_gueltig), 2=Cx2_keine_Positionsvorgabe_gueltig (CM_STRG1_Select_Positionsvorgabe_Cx2_keine_Positionsvorgabe_gueltig), 3=Cx3_Fehler (CM_STRG1_Select_Positionsvorgabe_Cx3_Fehler)}, range raw 0..3, transfer-property=PENDING  # Vorgabe der Gültigkeit der Positionsvorgaben, Steuerungsbotschaft für Aktuatoren
            signal STRG1_Geschwindigkeitsvorgabe_XIX_EVe_01_Control_XIX_Klima_LIN6: start 20, 4 bit, little-endian, data-type-policy=OVERRIDE, i-signal-type=PRIMITIVE, base-type=BT_STRG1_Geschwindigkeitsvorgabe, invalid-value=Invalid_STRG1_Geschwindigkeitsvorgabe_XIX_EVe_01_Control_XIX_Klima_LIN6:15, compu {0=Cx0_reserviert (CM_STRG1_Geschwindigkeitsvorgabe_Cx0_reserviert), 1=Cx1_Geschwindigkeitsstufe_1 (CM_STRG1_Geschwindigkeitsvorgabe_Cx1_Geschwindigkeitsstufe_1), 2=Cx2_Geschwindigkeitsstufe_2 (CM_STRG1_Geschwindigkeitsvorgabe_Cx2_Geschwindigkeitsstufe_2), 3=Cx3_Geschwindigkeitsstufe_3 (CM_STRG1_Geschwindigkeitsvorgabe_Cx3_Geschwindigkeitsstufe_3), 4=Cx4_Geschwindigkeitsstufe_4 (CM_STRG1_Geschwindigkeitsvorgabe_Cx4_Geschwindigkeitsstufe_4), 5=Cx5_Autospeed (CM_STRG1_Geschwindigkeitsvorgabe_Cx5_Autospeed), 15=Cxf_Fehler (CM_STRG1_Geschwindigkeitsvorgabe_Cxf_Fehler)}, range raw 0..15, transfer-property=PENDING  # Vorgabe der Geschwindigkeit, Steuerungsbotschaft für Aktuatoren
            signal STRG1_Soll_Position_Aktuator_XIX_EVe_01_Control_XIX_Klima_LIN6: start 24, 16 bit, little-endian, data-type-policy=OVERRIDE, i-signal-type=PRIMITIVE, base-type=BT_STRG1_Soll_Position_Aktuator, invalid-value=Invalid_STRG1_Soll_Position_Aktuator_XIX_EVe_01_Control_XIX_Klima_LIN6:65535, compu {phys=raw for raw 0..65534, 65535=Cxffff_Fehler (CM_STRG1_Soll_Position_Aktuator_Cxffff_Fehler); unit Unit_None}, range phys 0..65534 Unit_None, raw 0..65535, unit=Unit_None, transfer-property=PENDING  # Vorgabe der Sollposition, Steuerungsbotschaft für die Aktuatoren
            signal STRG1_Notlauffreigabe_XIX_EVe_01_Control_XIX_Klima_LIN6: start 56, 2 bit, little-endian, data-type-policy=OVERRIDE, i-signal-type=PRIMITIVE, base-type=BT_STRG1_Notlauffreigabe, invalid-value=Invalid_STRG1_Notlauffreigabe_XIX_EVe_01_Control_XIX_Klima_LIN6:3, compu {0=Cx0_Notlauf_aus (CM_STRG1_Notlauffreigabe_Cx0_Notlauf_aus), 1=Cx1_Notlauf_ein (CM_STRG1_Notlauffreigabe_Cx1_Notlauf_ein), 2=Cx2_reserviert (CM_STRG1_Notlauffreigabe_Cx2_reserviert), 3=Cx3_Fehler (CM_STRG1_Notlauffreigabe_Cx3_Fehler)}, range raw 0..3, transfer-property=PENDING  # Freigabe der Notlaufeigenschaft, Steuerungsbotschaft für Aktuatoren
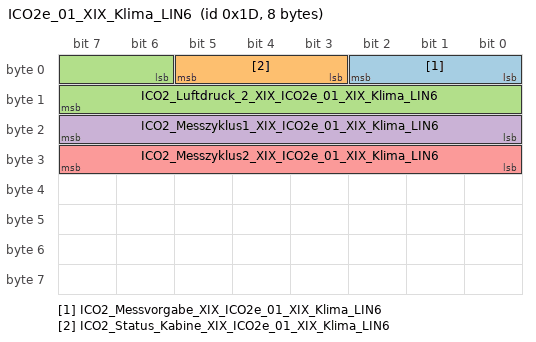
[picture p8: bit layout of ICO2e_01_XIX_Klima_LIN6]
        frame ICO2e_01_XIX_Klima_LIN6: id 0x1D, from Klima, frame-length=8, lin-checksum=ENHANCED
          pdu ICO2e_01_XIX_Klima_LIN6: length=8, unused-bit-pattern=0
            signal ICO2_Messvorgabe_XIX_ICO2e_01_XIX_Klima_LIN6: start 0, 3 bit, little-endian, data-type-policy=OVERRIDE, i-signal-type=PRIMITIVE, init-value=0, base-type=BT_ICO2_Messvorgabe, invalid-value=Invalid_ICO2_Messvorgabe_XIX_ICO2e_01_XIX_Klima_LIN6:7, compu {0=Cx0_keineUeberwachung (CM_ICO2_Messvorgabe_Cx0_keineUeberwachung), 1=Cx1_Fahrbetrieb (CM_ICO2_Messvorgabe_Cx1_Fahrbetrieb), 2=Cx2_Parkbetrieb (CM_ICO2_Messvorgabe_Cx2_Parkbetrieb), 7=Cx7_Fehler (CM_ICO2_Messvorgabe_Cx7_Fehler)}, range raw 0..7, transfer-property=PENDING  # Vorgabe für die Messmethode des Sensors
            signal ICO2_Status_Kabine_XIX_ICO2e_01_XIX_Klima_LIN6: start 3, 3 bit, little-endian, data-type-policy=OVERRIDE, i-signal-type=PRIMITIVE, init-value=0, base-type=BT_ICO2_Status_Kabine, invalid-value=Invalid_ICO2_Status_Kabine_XIX_ICO2e_01_XIX_Klima_LIN6:7, compu {0=Cx0_Geschlossen (CM_ICO2_Status_Kabine_Cx0_Geschlossen), 1=Cx1_LeichtOffen (CM_ICO2_Status_Kabine_Cx1_LeichtOffen), 2=Cx2_HalbOffen (CM_ICO2_Status_Kabine_Cx2_HalbOffen), 3=Cx3_VollOffen (CM_ICO2_Status_Kabine_Cx3_VollOffen), 7=Cx7_Fehler (CM_ICO2_Status_Kabine_Cx7_Fehler)}, range raw 0..7, transfer-property=PENDING  # Einfluss von Türen, Fenster, Schiebedach, Heckdeckel auf den Auswertealgorithmus
            signal ICO2_Luftdruck_2_XIX_ICO2e_01_XIX_Klima_LIN6: start 6, 10 bit, little-endian, data-type-policy=OVERRIDE, i-signal-type=PRIMITIVE, init-value=1022, base-type=BT_ICO2_Luftdruck_2, invalid-value=Invalid_ICO2_Luftdruck_2_XIX_ICO2e_01_XIX_Klima_LIN6:1023, compu {phys=raw+400 for raw 0..1000, 1021=Cx3fd_NichtVerfuegbar (CM_ICO2_Luftdruck_2_Cx3fd_NichtVerfuegbar), 1022=Cx3fe_InitWert (CM_ICO2_Luftdruck_2_Cx3fe_InitWert), 1023=Cx3ff_Fehler (CM_ICO2_Luftdruck_2_Cx3ff_Fehler); unit Unit_MilliBar}, range phys 400..1400 Unit_MilliBar, raw 0..1023, unit=Unit_MilliBar, transfer-property=PENDING  # Gemessener Luftdruck in hPa bzw. mbar
            signal ICO2_Messzyklus1_XIX_ICO2e_01_XIX_Klima_LIN6: start 16, 8 bit, little-endian, data-type-policy=OVERRIDE, i-signal-type=PRIMITIVE, init-value=0, base-type=BT_ICO2_Messzyklus1, compu {phys=raw for raw 0..255; unit Unit_None}, range phys 0..255 Unit_None, raw 0..255, unit=Unit_None, transfer-property=PENDING  # Vorgabe des Messzyklus für Phase 1
            signal ICO2_Messzyklus2_XIX_ICO2e_01_XIX_Klima_LIN6: start 24, 8 bit, little-endian, data-type-policy=OVERRIDE, i-signal-type=PRIMITIVE, init-value=0, base-type=BT_ICO2_Messzyklus2, compu {phys=raw for raw 0..255; unit Unit_None}, range phys 0..255 Unit_None, raw 0..255, unit=Unit_None, transfer-property=PENDING  # Vorgabe des Messzyklus für Phase 2
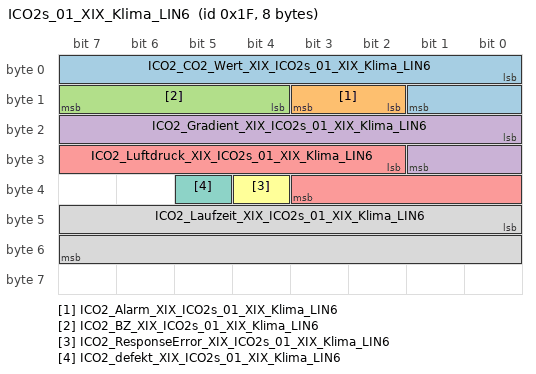
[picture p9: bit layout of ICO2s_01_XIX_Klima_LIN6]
        frame ICO2s_01_XIX_Klima_LIN6: id 0x1F, to Klima, frame-length=8, lin-checksum=ENHANCED
          pdu ICO2s_01_XIX_Klima_LIN6: length=8, unused-bit-pattern=0
            signal ICO2_CO2_Wert_XIX_ICO2s_01_XIX_Klima_LIN6: start 0, 10 bit, little-endian, data-type-policy=OVERRIDE, i-signal-type=PRIMITIVE, init-value=1022, base-type=BT_ICO2_CO2_Wert, invalid-value=Invalid_ICO2_CO2_Wert_XIX_ICO2s_01_XIX_Klima_LIN6:1023, compu {phys=raw*0.01 for raw 0..1000, 1022=Cx3fe_InitWert (CM_ICO2_CO2_Wert_Cx3fe_InitWert), 1023=Cx3ff_Fehler (CM_ICO2_CO2_Wert_Cx3ff_Fehler); unit Unit_KiloPascal}, range phys 0..10 Unit_KiloPascal, raw 0..1023, unit=Unit_KiloPascal, transfer-property=PENDING, to Klima(timeout 3.5 s)  # CO2-Wert als Partialdruck in kPa gemessen
            signal ICO2_Alarm_XIX_ICO2s_01_XIX_Klima_LIN6: start 10, 2 bit, little-endian, data-type-policy=OVERRIDE, i-signal-type=PRIMITIVE, init-value=0, base-type=BT_ICO2_Alarm, compu {0=Cx0_nicht_geschaltet (CM_ICO2_Alarm_Cx0_nicht_geschaltet), 1=Cx1_Gradient (CM_ICO2_Alarm_Cx1_Gradient), 2=Cx2_Limit (CM_ICO2_Alarm_Cx2_Limit)}, range raw 0..2, transfer-property=PENDING, to Klima(timeout 3.5 s)  # Grund für den Alarm (Weckursache für den LIN-Master)
            signal ICO2_BZ_XIX_ICO2s_01_XIX_Klima_LIN6: start 12, 4 bit, little-endian, data-type-policy=OVERRIDE, i-signal-type=PRIMITIVE, base-type=BT_ICO2_BZ, compu {phys=raw for raw 0..15; unit Unit_None}, range phys 0..15 Unit_None, raw 0..15, unit=Unit_None, transfer-property=PENDING, to Klima(timeout 3.5 s)  # Botschaftszähler / Alive-signal
            signal ICO2_Gradient_XIX_ICO2s_01_XIX_Klima_LIN6: start 16, 10 bit, little-endian, data-type-policy=OVERRIDE, i-signal-type=PRIMITIVE, init-value=1022, base-type=BT_ICO2_Gradient, invalid-value=Invalid_ICO2_Gradient_XIX_ICO2s_01_XIX_Klima_LIN6:1023, compu {phys=raw*100-50000 for raw 0..1000, 1022=Cx3fe_Init (CM_ICO2_Gradient_Cx3fe_Init), 1023=Cx3ff_Fehler (CM_ICO2_Gradient_Cx3ff_Fehler); unit Unit_None}, range phys -50000..50000 Unit_None, raw 0..1023, unit=Unit_None, transfer-property=PENDING, to Klima(timeout 3.5 s)  # CO2-Anstieg bzw. CO2-Abfall in ppm innerhalb der applizierten Zeit
            signal ICO2_Luftdruck_XIX_ICO2s_01_XIX_Klima_LIN6: start 26, 10 bit, little-endian, data-type-policy=OVERRIDE, i-signal-type=PRIMITIVE, init-value=1022, base-type=BT_ICO2_Luftdruck, invalid-value=Invalid_ICO2_Luftdruck_XIX_ICO2s_01_XIX_Klima_LIN6:1023, compu {phys=raw+400 for raw 0..1000, 1021=Cx3fd_NichtVerfuegbar (CM_ICO2_Luftdruck_Cx3fd_NichtVerfuegbar), 1022=Cx3fe_Init (CM_ICO2_Luftdruck_Cx3fe_Init), 1023=Cx3ff_Fehler (CM_ICO2_Luftdruck_Cx3ff_Fehler); unit Unit_MilliBar}, range phys 400..1400 Unit_MilliBar, raw 0..1023, unit=Unit_MilliBar, transfer-property=PENDING, to Klima(timeout 3.5 s)  # Gemessener Luftdruck in hPa bzw. mBar
            signal ICO2_ResponseError_XIX_ICO2s_01_XIX_Klima_LIN6: start 36, 1 bit, little-endian, data-type-policy=OVERRIDE, i-signal-type=PRIMITIVE, init-value=0, base-type=BT_ICO2_ResponseError, invalid-value=Invalid_ICO2_ResponseError_XIX_ICO2s_01_XIX_Klima_LIN6:1, compu {0=Cx0_normal (CM_ICO2_ResponseError_Cx0_normal), 1=Cx1_Fehler (CM_ICO2_ResponseError_Cx1_Fehler)}, range raw 0..1, transfer-property=PENDING, to Klima(timeout 3.5 s)  # siehe LIN2.0-Specification
            signal ICO2_defekt_XIX_ICO2s_01_XIX_Klima_LIN6: start 37, 1 bit, little-endian, data-type-policy=OVERRIDE, i-signal-type=PRIMITIVE, init-value=0, base-type=BT_ICO2_defekt, compu {0=Cx0_iO (CM_ICO2_defekt_Cx0_iO), 1=Cx1_defekt (CM_ICO2_defekt_Cx1_defekt)}, range raw 0..1, transfer-property=PENDING, to Klima(timeout 3.5 s)  # CO2 Sensor Defekt erkannt
            signal ICO2_Laufzeit_XIX_ICO2s_01_XIX_Klima_LIN6: start 40, 16 bit, little-endian, data-type-policy=OVERRIDE, i-signal-type=PRIMITIVE, init-value=65534, base-type=BT_ICO2_Laufzeit, invalid-value=Invalid_ICO2_Laufzeit_XIX_ICO2s_01_XIX_Klima_LIN6:65535, compu {phys=raw*10 for raw 0..65533, 65534=Cxfffe_Init (CM_ICO2_Laufzeit_Cxfffe_Init), 65535=Cxffff_Fehler (CM_ICO2_Laufzeit_Cxffff_Fehler); unit Unit_Secon}, range phys 0..655330 Unit_Secon, raw 0..65535, unit=Unit_Secon, transfer-property=PENDING, to Klima(timeout 3.5 s)  # Laufzeit des aktuellen bzw. letzten Überwachungsmodus
        frame MasterReq_XIX_Klima_LIN6: id 0x3C, from Klima, frame-length=8, lin-checksum=CLASSIC
          n pdu MasterReq_XIX_Klima_LIN6: length=8
        frame SlaveResp_XIX_Klima_LIN6: id 0x3D, to Klima, frame-length=8, lin-checksum=CLASSIC
          n pdu SlaveResp_XIX_Klima_LIN6: length=8
        pdu triggering PT_Klima_LIN6_XIX_TPCHType_LIN_Diagnose_XIX_0x0_XIX_0x1_XIX_Physical: pdu=DCM_Klima_LIN6_XIX_TPCHType_LIN_Diagnose_XIX_0x0_XIX_0x1_XIX_Physical, from Klima
        pdu triggering PT_Klima_LIN6_XIX_TPCHType_LIN_Diagnose_XIX_0x0_XIX_0x23_XIX_Physical: pdu=DCM_Klima_LIN6_XIX_TPCHType_LIN_Diagnose_XIX_0x0_XIX_0x23_XIX_Physical, from Klima
        pdu triggering PT_Klima_LIN6_XIX_TPCHType_LIN_Diagnose_XIX_0x0_XIX_0x{25..28}_XIX_Physical: pdu=DCM_Klima_LIN6_XIX_TPCHType_LIN_Diagnose_XIX_0x0_XIX_0x{25..28}_XIX_Physical, from Klima
        pdu triggering PT_Klima_LIN6_XIX_TPCHType_LIN_Diagnose_XIX_0x0_XIX_0x2_XIX_Physical: pdu=DCM_Klima_LIN6_XIX_TPCHType_LIN_Diagnose_XIX_0x0_XIX_0x2_XIX_Physical, from Klima
        pdu triggering PT_Klima_LIN6_XIX_TPCHType_LIN_Diagnose_XIX_0x0_XIX_0x3_XIX_Physical: pdu=DCM_Klima_LIN6_XIX_TPCHType_LIN_Diagnose_XIX_0x0_XIX_0x3_XIX_Physical, from Klima
        pdu triggering PT_Klima_LIN6_XIX_TPCHType_LIN_Diagnose_XIX_0x0_XIX_0x43_XIX_Physical: pdu=DCM_Klima_LIN6_XIX_TPCHType_LIN_Diagnose_XIX_0x0_XIX_0x43_XIX_Physical, from Klima
        pdu triggering PT_Klima_LIN6_XIX_TPCHType_LIN_Diagnose_XIX_0x1_XIX_0x0_XIX_Physical: pdu=DCM_Klima_LIN6_XIX_TPCHType_LIN_Diagnose_XIX_0x1_XIX_0x0_XIX_Physical, to Klima
        pdu triggering PT_Klima_LIN6_XIX_TPCHType_LIN_Diagnose_XIX_0x23_XIX_0x0_XIX_Physical: pdu=DCM_Klima_LIN6_XIX_TPCHType_LIN_Diagnose_XIX_0x23_XIX_0x0_XIX_Physical, to Klima
        pdu triggering PT_Klima_LIN6_XIX_TPCHType_LIN_Diagnose_XIX_0x{25..28}_XIX_0x0_XIX_Physical: pdu=DCM_Klima_LIN6_XIX_TPCHType_LIN_Diagnose_XIX_0x{25..28}_XIX_0x0_XIX_Physical, to Klima
        pdu triggering PT_Klima_LIN6_XIX_TPCHType_LIN_Diagnose_XIX_0x2_XIX_0x0_XIX_Physical: pdu=DCM_Klima_LIN6_XIX_TPCHType_LIN_Diagnose_XIX_0x2_XIX_0x0_XIX_Physical, to Klima
        pdu triggering PT_Klima_LIN6_XIX_TPCHType_LIN_Diagnose_XIX_0x3_XIX_0x0_XIX_Physical: pdu=DCM_Klima_LIN6_XIX_TPCHType_LIN_Diagnose_XIX_0x3_XIX_0x0_XIX_Physical, to Klima
        pdu triggering PT_Klima_LIN6_XIX_TPCHType_LIN_Diagnose_XIX_0x43_XIX_0x0_XIX_Physical: pdu=DCM_Klima_LIN6_XIX_TPCHType_LIN_Diagnose_XIX_0x43_XIX_0x0_XIX_Physical, to Klima
        5 x lin schedule table, all with resume-position=CONTINUE-AT-IT-POSITION:
          DiagRequest: run-mode=RUN-ONCE, application-entry{delay=0.01, position-in-table=0, frame-triggering=CHNL/FT_MasterReq}
          DiagResponse: run-mode=RUN-ONCE, application-entry{delay=0.01, position-in-table=0, frame-triggering=CHNL/FT_SlaveResp}
          st_main_1: run-mode=RUN-CONTINUOUS
            table-entrys:
              delay=0.03, position-in-table=0, frame-triggering=CHNL/FT_EVe_01_Control
              delay=0.01, position-in-table=1, frame-triggering=FT_EASV1s_01_Status
              delay=0.01, position-in-table=2, frame-triggering=FT_DTS2s_R744_01
              delay=0.01, position-in-table=3, frame-triggering=FT_ICO2e_01
              delay=0.01, position-in-table=4, frame-triggering=FT_EASV2s_01_Status
              delay=0.01, position-in-table=5, frame-triggering=FT_DTS3s_R744_01
              delay=0.02, position-in-table=6, frame-triggering=FT_DTS1s_R744_01
              delay=0.03, position-in-table=7, frame-triggering=FT_EASV3s_01_Status
              delay=0.01, position-in-table=8, frame-triggering=FT_EASV4s_01_Status
              delay=0.01, position-in-table=9, frame-triggering=FT_DTS2s_R744_01
              delay=0.01, position-in-table=10, frame-triggering=FT_ICO2s_01
              delay=0.01, position-in-table=11, frame-triggering=FT_EASV5s_01_Status
              delay=0.01, position-in-table=12, frame-triggering=FT_DTS3s_R744_01
              delay=0.02, position-in-table=13, frame-triggering=FT_DTS1s_R744_01
          st_main_2: run-mode=RUN-CONTINUOUS
            table-entrys:
              delay=0.01, position-in-table=0, frame-triggering=CHNL/FT_EVe_01_Control
              delay=0.01, position-in-table=1, frame-triggering=FT_BLOWER1c_SET
              delay=0.01, position-in-table=2, frame-triggering=FT_BLOWER2b_SET
              delay=0.01, position-in-table=3, frame-triggering=FT_EASV1s_01_Status
              delay=0.01, position-in-table=4, frame-triggering=FT_DTS2s_R744_01
              delay=0.01, position-in-table=5, frame-triggering=FT_ICO2e_01
              delay=0.01, position-in-table=6, frame-triggering=FT_EASV2s_01_Status
              delay=0.01, position-in-table=7, frame-triggering=FT_DTS3s_R744_01
              delay=0.02, position-in-table=8, frame-triggering=FT_DTS1s_R744_01
              delay=0.01, position-in-table=9, frame-triggering=FT_EASV3s_01_Status
              delay=0.01, position-in-table=10, frame-triggering=FT_BLOWER1c_STATUS
              delay=0.01, position-in-table=11, frame-triggering=FT_BLOWER2b_STATUS
              delay=0.01, position-in-table=12, frame-triggering=FT_EASV4s_01_Status
              delay=0.01, position-in-table=13, frame-triggering=FT_DTS2s_R744_01
              delay=0.01, position-in-table=14, frame-triggering=FT_ICO2s_01
              delay=0.01, position-in-table=15, frame-triggering=FT_EASV5s_01_Status
              delay=0.01, position-in-table=16, frame-triggering=FT_DTS3s_R744_01
              delay=0.02, position-in-table=17, frame-triggering=FT_DTS1s_R744_01
          st_main_3: run-mode=RUN-CONTINUOUS
            table-entrys:
              delay=0.01, position-in-table=0, frame-triggering=FT_DTS2s_R744_01
              delay=0.02, position-in-table=1, frame-triggering=FT_ICO2e_01
              delay=0.01, position-in-table=2, frame-triggering=FT_DTS3s_R744_01
              delay=0.06, position-in-table=3, frame-triggering=FT_DTS1s_R744_01
              delay=0.01, position-in-table=4, frame-triggering=FT_DTS2s_R744_01
              delay=0.02, position-in-table=5, frame-triggering=FT_ICO2s_01
              delay=0.01, position-in-table=6, frame-triggering=FT_DTS3s_R744_01
              delay=0.06, position-in-table=7, frame-triggering=FT_DTS1s_R744_01
